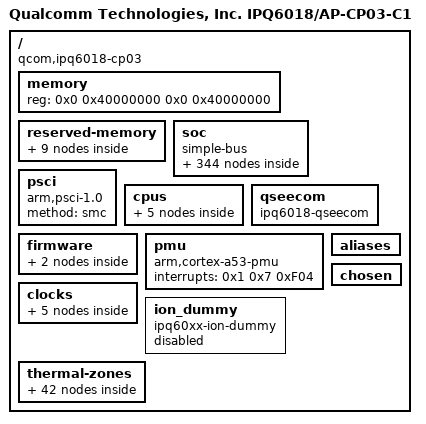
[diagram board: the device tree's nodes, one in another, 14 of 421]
/dts-v1/;
// version: 17
// last_comp_version: 16
// boot_cpuid_phys: 0x0

/ {
    model = "Qualcomm Technologies, Inc. IPQ6018/AP-CP03-C1";
    compatible = "qcom,ipq6018-cp03", "qcom,ipq6018";
    qcom,board-id = <0x8 0x0>;
    qcom,pmic-id = <0x0 0x0 0x0 0x0>;
    #address-cells = <0x2>;
    #size-cells = <0x2>;
    interrupt-parent = <0x1>;
    qcom,msm-id = <0x1A5 0x0>;
    memory {
        device_type = "memory";
        reg = <0x0 0x40000000 0x0 0x40000000>;
    };
    reserved-memory {
        #address-cells = <0x2>;
        #size-cells = <0x2>;
        ranges;
        nss@40000000 {
            no-map;
            reg = <0x0 0x40000000 0x0 0x1000000>;
        };
        uboot@4A100000 {
            no-map;
            reg = <0x0 0x4A100000 0x0 0x400000>;
        };
        sbl@4A500000 {
            no-map;
            reg = <0x0 0x4A500000 0x0 0x100000>;
        };
        tz@4A600000 {
            no-map;
            reg = <0x0 0x4A600000 0x0 0x400000>;
        };
        smem@4AA00000 {
            no-map;
            reg = <0x0 0x4AA00000 0x0 0x100000>;
            linux,phandle = <0x11>;
            phandle = <0x11>;
        };
        wcnss@4ab00000 {
            no-map;
            reg = <0x0 0x4AB00000 0x0 0x5500000>;
            linux,phandle = <0x17>;
            phandle = <0x17>;
        };
        q6_etr_dump@1 {
            no-map;
            reg = <0x0 0x50000000 0x0 0x100000>;
            linux,phandle = <0x18>;
            phandle = <0x18>;
        };
        rpm_msg_ram@0x60000 {
            no-map;
            reg = <0x0 0x60000 0x0 0x6000>;
            linux,phandle = <0x13>;
            phandle = <0x13>;
        };
        tzapp@49B00000 {
            no-map;
            reg = <0x0 0x49B00000 0x0 0x600000>;
        };
    };
    soc {
        #address-cells = <0x1>;
        #size-cells = <0x1>;
        ranges = <0x0 0x0 0x0 0xFFFFFFFF>;
        compatible = "simple-bus";
        wifi1@f00000 {
            compatible = "qcom,cnss-qcn9000";
            qcom,wlan-ramdump-dynamic = <0x400000>;
            status = "disabled";
            mhi,max-channels = <0x1E>;
            mhi,timeout = <0x2710>;
            #address-cells = <0x1>;
            #size-cells = <0x0>;
            base-addr = <0x50100000>;
            caldb-addr = <0x53000000>;
            qrtr_node_id = <0x20>;
            qca,auto-restart;
            mhi_channels {
                mhi_chan@0 {
                    reg = <0x0>;
                    label = "LOOPBACK";
                    mhi,num-elements = <0x20>;
                    mhi,event-ring = <0x1>;
                    mhi,chan-dir = <0x1>;
                    mhi,data-type = <0x0>;
                    mhi,doorbell-mode = <0x2>;
                    mhi,ee = <0x14>;
                };
                mhi_chan@1 {
                    reg = <0x1>;
                    label = "LOOPBACK";
                    mhi,num-elements = <0x20>;
                    mhi,event-ring = <0x1>;
                    mhi,chan-dir = <0x2>;
                    mhi,data-type = <0x0>;
                    mhi,doorbell-mode = <0x2>;
                    mhi,ee = <0x14>;
                };
                mhi_chan@4 {
                    reg = <0x4>;
                    label = "DIAG";
                    mhi,num-elements = <0x20>;
                    mhi,event-ring = <0x1>;
                    mhi,chan-dir = <0x1>;
                    mhi,data-type = <0x0>;
                    mhi,doorbell-mode = <0x2>;
                    mhi,ee = <0x14>;
                };
                mhi_chan@5 {
                    reg = <0x5>;
                    label = "DIAG";
                    mhi,num-elements = <0x20>;
                    mhi,event-ring = <0x1>;
                    mhi,chan-dir = <0x2>;
                    mhi,data-type = <0x0>;
                    mhi,doorbell-mode = <0x2>;
                    mhi,ee = <0x14>;
                };
                mhi_chan@20 {
                    reg = <0x14>;
                    label = "IPCR";
                    mhi,num-elements = <0x20>;
                    mhi,event-ring = <0x1>;
                    mhi,chan-dir = <0x1>;
                    mhi,data-type = <0x1>;
                    mhi,doorbell-mode = <0x2>;
                    mhi,ee = <0x14>;
                    mhi,auto-start;
                };
                mhi_chan@21 {
                    reg = <0x15>;
                    label = "IPCR";
                    mhi,num-elements = <0x20>;
                    mhi,event-ring = <0x1>;
                    mhi,chan-dir = <0x2>;
                    mhi,data-type = <0x0>;
                    mhi,doorbell-mode = <0x2>;
                    mhi,ee = <0x14>;
                    mhi,auto-queue;
                    mhi,auto-start;
                };
            };
            mhi_events {
                mhi_event@0 {
                    mhi,num-elements = <0x20>;
                    mhi,intmod = <0x1>;
                    mhi,msi = <0x1>;
                    mhi,priority = <0x1>;
                    mhi,brstmode = <0x2>;
                    mhi,data-type = <0x1>;
                };
                mhi_event@1 {
                    mhi,num-elements = <0x100>;
                    mhi,intmod = <0x1>;
                    mhi,msi = <0x2>;
                    mhi,priority = <0x1>;
                    mhi,brstmode = <0x2>;
                };
            };
            mhi_devices {
                mhi_qrtr {
                    mhi,chan = "IPCR";
                    qcom,net-id = <0x0>;
                };
            };
        };
        interrupt-controller@b000000 {
            compatible = "qcom,msm-qgic2";
            interrupt-controller;
            #interrupt-cells = <0x3>;
            reg = <0xB000000 0x1000 0xB002000 0x1000>;
            linux,phandle = <0x1>;
            phandle = <0x1>;
        };
        timer {
            compatible = "arm,armv8-timer";
            interrupts = <0x1 0x2 0xF08 0x1 0x3 0xF08 0x1 0x4 0xF08 0x1 0x1 0xF08>;
            clock-frequency = <0x16E3600>;
            always-on;
        };
        gcc@1800000 {
            compatible = "qcom,gcc-ipq6018";
            reg = <0x1800000 0x80000>;
            #clock-cells = <0x1>;
            #reset-cells = <0x1>;
            linux,phandle = <0x3>;
            phandle = <0x3>;
        };
        qcom,apss_clk@b111000 {
            compatible = "qcom,apss-ipq6018";
            reg = <0xB111000 0x6000>;
            #clock-cells = <0x1>;
            #reset-cells = <0x1>;
            linux,phandle = <0x4F>;
            phandle = <0x4F>;
        };
        arm,smmu@1E00000 {
            compatible = "arm,smmu-v2";
            reg = <0x1E00000 0x40000>;
            #iommu-cells = <0x1>;
            #global-interrupts = <0x1>;
            qcom,skip-init;
            interrupts = <0x0 0x29 0x4 0x0 0x46 0x4 0x0 0x47 0x4 0x0 0x49 0x4 0x0 0xF0 0x4 0x0 0xF1 0x4 0x0 0xF2 0x4 0x0 0xF5 0x4 0x0 0xF6 0x4 0x0 0xF7 0x4 0x0 0xF8 0x4 0x0 0xF9 0x4 0x0 0xFA 0x4 0x0 0xFB 0x4 0x0 0xFC 0x4 0x0 0xFD 0x4 0x0 0xFE 0x4 0x0 0xFF 0x4 0x0 0x35 0x4 0x0 0x36 0x4 0x0 0x3A 0x4 0x0 0x3C 0x4 0x0 0x3D 0x4 0x0 0x4C 0x4 0x0 0x4D 0x4 0x0 0x50 0x4 0x0 0x5E 0x4 0x0 0x65 0x4 0x0 0x66 0x4 0x0 0x67 0x4 0x0 0x68 0x4 0x0 0x69 0x4 0x0 0x6A 0x4>;
            status = "disabled";
            linux,phandle = <0x2>;
            phandle = <0x2>;
        };
        qcom,msm-adsprpc-mem {
            compatible = "qcom,msm-adsprpc-mem-region";
            status = "disabled";
        };
        qcom,msm_fastrpc {
            compatible = "qcom,msm-fastrpc-compute";
            qcom,rpc-latency-us = <0x263>;
            qcom,fastrpc-adsp-audio-pdr;
            qcom,fastrpc-adsp-sensors-pdr;
            qcom,fastrpc-legacy-remote-heap;
            status = "disabled";
            qcom,msm_fastrpc_compute_cb1 {
                compatible = "qcom,msm-fastrpc-compute-cb";
                label = "adsprpc-smd";
                iommus = <0x2 0x1004>;
            };
            qcom,msm_fastrpc_compute_cb2 {
                compatible = "qcom,msm-fastrpc-compute-cb";
                label = "adsprpc-smd";
                iommus = <0x2 0x1005>;
            };
            qcom,msm_fastrpc_compute_cb3 {
                compatible = "qcom,msm-fastrpc-compute-cb";
                label = "adsprpc-smd";
                iommus = <0x2 0x1006>;
            };
            qcom,msm_fastrpc_compute_cb4 {
                compatible = "qcom,msm-fastrpc-compute-cb";
                label = "adsprpc-smd";
                iommus = <0x2 0x1007>;
            };
            qcom,msm_fastrpc_compute_cb5 {
                compatible = "qcom,msm-fastrpc-compute-cb";
                label = "adsprpc-smd";
                iommus = <0x2 0x1008>;
            };
            qcom,msm_fastrpc_compute_cb6 {
                compatible = "qcom,msm-fastrpc-compute-cb";
                label = "adsprpc-smd";
                iommus = <0x2 0x1009>;
            };
            qcom,msm_fastrpc_compute_cb7 {
                compatible = "qcom,msm-fastrpc-compute-cb";
                label = "adsprpc-smd";
                iommus = <0x2 0x100A>;
            };
            qcom,msm_fastrpc_compute_cb8 {
                compatible = "qcom,msm-fastrpc-compute-cb";
                label = "adsprpc-smd";
                iommus = <0x2 0x100B>;
            };
        };
        serial@78b3000 {
            compatible = "qcom,msm-uartdm-v1.4", "qcom,msm-uartdm";
            reg = <0x78B3000 0x200>;
            interrupts = <0x0 0x134 0x4>;
            clocks = <0x3 0x54 0x3 0x43>;
            clock-names = "core", "iface";
            status = "disabled";
        };
        serial@78af000 {
            compatible = "qcom,msm-uartdm-v1.4", "qcom,msm-uartdm";
            reg = <0x78AF000 0x200>;
            interrupts = <0x0 0x6B 0x4>;
            clocks = <0x3 0x50 0x3 0x43>;
            clock-names = "core", "iface";
            status = "disabled";
        };
        serial@78b0000 {
            compatible = "qcom,msm-uartdm-v1.4", "qcom,msm-uartdm";
            reg = <0x78B0000 0x200>;
            interrupts = <0x0 0x6C 0x4>;
            clocks = <0x3 0x51 0x3 0x43>;
            clock-names = "core", "iface";
            status = "disabled";
        };
        serial@78b1000 {
            compatible = "qcom,msm-uartdm-v1.4", "qcom,msm-uartdm";
            reg = <0x78B1000 0x200>;
            interrupts = <0x0 0x132 0x4>;
            clocks = <0x3 0x52 0x3 0x43>;
            clock-names = "core", "iface";
            status = "ok";
            pinctrl-0 = <0x4>;
            pinctrl-names = "default";
        };
        qrng@e1000 {
            compatible = "qcom,prng-ipq807x";
            reg = <0xE3000 0x1000>;
            clocks = <0x3 0x88>;
            clock-names = "core";
            status = "ok";
        };
        dma@704000 {
            compatible = "qcom,bam-v1.7.0";
            reg = <0x704000 0x20000>;
            interrupts = <0x0 0xCF 0x0>;
            clocks = <0x3 0x56>;
            clock-names = "bam_clk";
            #dma-cells = <0x1>;
            qcom,ee = <0x1>;
            qcom,controlled-remotely = <0x1>;
            qcom,config-pipe-trust-reg = <0x0>;
            linux,phandle = <0x5>;
            phandle = <0x5>;
        };
        crypto@73a000 {
            compatible = "qcom,crypto-v5.1";
            reg = <0x73A000 0x6000>;
            clocks = <0x3 0x56 0x3 0x57 0x3 0x58>;
            clock-names = "iface", "bus", "core";
            dmas = <0x5 0x2 0x5 0x3>;
            dma-names = "rx", "tx";
        };
        qcom_mdss_qpic@7980000 {
            compatible = "qcom,mdss_qpic";
            reg = <0x7980000 0x24000>;
            interrupts = <0x0 0x97 0x0>;
            clocks = <0x3 0x8A 0x3 0x89>;
            clock-names = "core", "aon";
            dmas = <0x6 0x6>;
            dma-names = "chan";
            status = "disabled";
        };
        qcom_mdss_qpic_panel {
            compatible = "qcom,mdss-qpic-panel";
            label = "qpic lcd panel";
            qcom,mdss-pan-res = <0x320 0x1E0>;
            qcom,mdss-pan-bpp = <0x12>;
            qcom,refresh_rate = <0x3C>;
            status = "disabled";
        };
        ssphy@78000 {
            compatible = "qcom,usb-ssphy-qmp";
            reg = <0x78000 0x45C 0x193F244 0x4 0x8AF8800 0x100 0x7E000 0x18>;
            reg-names = "qmp_phy_base", "vls_clamp_reg", "qscratch_base", "ahb2phy_base";
            qcom,qmp-phy-init-seq = <0xAC 0x14 0x1A 0x0 0x34 0x8 0x8 0x0 0x174 0x30 0x30 0x0 0x3C 0x6 0x6 0x0 0xB4 0x0 0x0 0x0 0xB8 0x8 0x8 0x0 0x194 0x6 0x6 0x3E8 0x19C 0x1 0x1 0x0 0x178 0x0 0x0 0x0 0xD0 0x68 0x68 0x0 0xDC 0xAB 0xAB 0x0 0xE0 0xAA 0xAA 0x0 0xE4 0x2 0x2 0x0 0x78 0x9 0x9 0x0 0x84 0x16 0x16 0x0 0x90 0x28 0x28 0x0 0x108 0xA0 0xA0 0x0 0x10C 0x0 0x0 0x0 0x184 0xA 0xA 0x0 0x4C 0xAA 0xAA 0x0 0x50 0x29 0x29 0x0 0x54 0x0 0x0 0x0 0xC8 0x0 0x0 0x0 0x18C 0x0 0x0 0x0 0xCC 0x0 0x0 0x0 0x128 0x0 0x0 0x0 0xC 0xA 0xA 0x0 0x10 0x1 0x1 0x0 0x1C 0x7D 0x7D 0x0 0x20 0x1 0x1 0x0 0x14 0x0 0x0 0x0 0x18 0x0 0x0 0x0 0x24 0xA 0xA 0x0 0x28 0x5 0x5 0x0 0x48 0xF 0xF 0x0 0x70 0xF 0xF 0x0 0x100 0x80 0x80 0x0 0x440 0xB 0xB 0x0 0x4D8 0x2 0x2 0x0 0x4DC 0x6C 0x6C 0x0 0x4E0 0xBB 0xB8 0x0 0x508 0x77 0x77 0x0 0x50C 0x80 0x80 0x0 0x514 0x3 0x3 0x0 0x51C 0x16 0x16 0x0 0x448 0x75 0x75 0x0 0x454 0x0 0x0 0x0 0x40C 0xA 0xA 0x0 0x41C 0x6 0x6 0x0 0x510 0x0 0x0 0x0 0x268 0x45 0x45 0x0 0x2AC 0x12 0x12 0x0 0x294 0x6 0x6 0x0 0x254 0x0 0x0 0x0 0x8C8 0x83 0x83 0x0 0x8C4 0x2 0x2 0x0 0x8CC 0x9 0x9 0x0 0x8D0 0xA2 0xA2 0x0 0x8D4 0x85 0x85 0x0 0x880 0xD1 0xD1 0x0 0x884 0x1F 0x1F 0x0 0x888 0x47 0x47 0x0 0x80C 0x9F 0x9F 0x0 0x824 0x17 0x17 0x0 0x828 0xF 0xF 0x0 0x8B8 0x75 0x75 0x0 0x8BC 0x13 0x13 0x0 0x8B0 0x86 0x86 0x0 0x8A0 0x4 0x4 0x0 0x88C 0x44 0x44 0x0 0x870 0xE7 0xE7 0x0 0x874 0x3 0x3 0x0 0x878 0x40 0x40 0x0 0x87C 0x0 0x0 0x0 0x9D8 0x88 0x88 0x0 0xFFFFFFFF 0xFFFFFFFF 0x0 0x0>;
            qcom,qmp-phy-reg-offset = <0x988 0x98C 0x990 0x994 0x974 0x8D8 0x8DC 0x804 0x800 0x808>;
            clocks = <0x3 0x9D 0x3 0xA1>;
            clock-names = "aux_clk", "pipe_clk";
            resets = <0x3 0x27 0x3 0x28>;
            reset-names = "usb3_phy_reset", "usb3phy_phy_reset";
            status = "ok";
            linux,phandle = <0x9>;
            phandle = <0x9>;
        };
        qusb@79000 {
            compatible = "qcom,qusb2phy";
            reg = <0x79000 0x180 0x8AF8800 0x400 0x1841030 0x4 0x8A0C12C 0x4>;
            reg-names = "qusb_phy_base", "qscratch_base", "ref_clk_addr", "usb3_guctl_addr";
            qcom,qusb-phy-init-seq = <0x14 0x0 0xF8 0x80 0xB3 0x84 0x83 0x88 0xC0 0x8C 0x30 0x8 0x79 0xC 0x21 0x10 0x0 0x90 0x0 0x18 0x14 0x9C 0x80 0x4 0x9F 0x1C>;
            phy_type = "utmi";
            resets = <0x3 0x2B>;
            reset-names = "usb2_phy_reset";
            status = "ok";
            linux,phandle = <0x8>;
            phandle = <0x8>;
        };
        qusb@59000 {
            compatible = "qcom,qusb2phy";
            reg = <0x59000 0x180 0x70F8800 0x400 0x1841030 0x4 0x700C12C 0x4>;
            reg-names = "qusb_phy_base", "qscratch_base", "ref_clk_addr", "usb3_guctl_addr";
            qcom,qusb-phy-init-seq = <0x14 0x0 0xF8 0x80 0xB3 0x84 0x83 0x88 0xC0 0x8C 0x30 0x8 0x79 0xC 0x21 0x10 0x0 0x90 0x0 0x18 0x14 0x9C 0x80 0x4 0x9F 0x1C>;
            phy_type = "utmi";
            resets = <0x3 0x2C>;
            reset-names = "usb2_phy_reset";
            status = "disabled";
            linux,phandle = <0xA>;
            phandle = <0xA>;
        };
        dbm@0x8AF8000 {
            compatible = "qcom,usb-dbm-1p5";
            reg = <0x8AF8000 0x300>;
            qcom,reset-ep-after-lpm-resume;
            linux,phandle = <0x7>;
            phandle = <0x7>;
        };
        usb3@8A00000 {
            compatible = "qcom,ipq6018-dwc3";
            #address-cells = <0x1>;
            #size-cells = <0x1>;
            ranges;
            reg = <0x8AF8800 0x100 0x8A00000 0xCD00>;
            reg-names = "qscratch_base", "dwc3_base";
            clocks = <0x3 0xB9 0x3 0xBA 0x3 0x9E 0x3 0xA2 0x3 0x9F 0x3 0xA0 0x3 0x9D 0x3 0xA1>;
            clock-names = "snoc_bus_timeout2", "sys_noc_axi", "master", "sleep", "mock_utmi", "cfg_ahb_clk", "aux_clk", "pipe_clk";
            assigned-clocks = <0x3 0xBA 0x3 0x9E 0x3 0x9F>;
            assigned-clock-rates = <0x7F27450 0x7F27450 0x16E3600>;
            qca,host = <0x1>;
            qcom,usb-dbm = <0x7>;
            status = "ok";
            dwc3@8A00000 {
                compatible = "snps,dwc3";
                reg = <0x8A00000 0xCD00>;
                interrupts = <0x0 0x8C 0x0>;
                usb-phy = <0x8 0x9>;
                snps,dis_ep_cache_eviction;
                tx-fifo-resize;
                snps,usb3-u1u2-disable;
                snps,nominal-elastic-buffer;
                snps,is-utmi-l1-suspend;
                snps,hird-threshold = [00];
                snps,dis_u2_susphy_quirk;
                snps,dis_u3_susphy_quirk;
                snps,quirk-ref-clock-adjustment = <0xA87F0>;
                snps,quirk-ref-clock-period = <0x29>;
                dr_mode = "host";
            };
        };
        qcom,usbbam@8B04000 {
            compatible = "qcom,usb-bam-msm";
            reg = <0x8B04000 0x17000>;
            interrupt-parent = <0x1>;
            interrupts = <0x0 0x87 0x0>;
            qcom,bam-type = <0x0>;
            qcom,usb-bam-fifo-baseaddr = <0x4A100000>;
            qcom,usb-bam-num-pipes = <0x4>;
            qcom,ignore-core-reset-ack;
            qcom,disable-clk-gating;
            qcom,usb-bam-override-threshold = <0x4001>;
            qcom,usb-bam-max-mbps-highspeed = <0x190>;
            qcom,usb-bam-max-mbps-superspeed = <0xE10>;
            qcom,reset-bam-on-connect;
            qcom,pipe0 {
                label = "ssusb-qdss-in-0";
                qcom,usb-bam-mem-type = <0x2>;
                qcom,dir = <0x1>;
                qcom,pipe-num = <0x0>;
                qcom,peer-bam = <0x0>;
                qcom,peer-bam-physical-address = <0x6064000>;
                qcom,src-bam-pipe-index = <0x0>;
                qcom,dst-bam-pipe-index = <0x0>;
                qcom,data-fifo-offset = <0x0>;
                qcom,data-fifo-size = <0xE00>;
                qcom,descriptor-fifo-offset = <0xE00>;
                qcom,descriptor-fifo-size = <0x200>;
            };
        };
        extcon_usb {
            compatible = "linux,extcon-usb-gpio";
            status = "disabled";
        };
        usb2@7000000 {
            compatible = "qcom,ipq6018-dwc3";
            #address-cells = <0x1>;
            #size-cells = <0x1>;
            ranges;
            reg = <0x70F8800 0x100 0x7000000 0xCD00>;
            reg-names = "qscratch_base", "dwc3_base";
            clocks = <0x3 0xA3 0x3 0xA6 0x3 0xA4 0x3 0xA5>;
            clock-names = "master", "sleep", "mock_utmi", "cfg_ahb_clk";
            assigned-clocks = <0x3 0xA3 0x3 0xA4>;
            assigned-clock-rates = <0x7F27450 0x16E3600>;
            qca,host = <0x1>;
            status = "disabled";
            dwc3@7000000 {
                compatible = "snps,dwc3";
                reg = <0x7000000 0xCD00>;
                interrupts = <0x0 0x63 0x0>;
                usb-phy = <0xA>;
                snps,dis_ep_cache_eviction;
                tx-fifo-resize;
                snps,usb3-u1u2-disable;
                snps,nominal-elastic-buffer;
                snps,is-utmi-l1-suspend;
                snps,hird-threshold = [00];
                snps,dis_u2_susphy_quirk;
                snps,dis_u3_susphy_quirk;
                snps,quirk-ref-clock-adjustment = <0xA87F0>;
                snps,quirk-ref-clock-period = <0x29>;
                dr_mode = "host";
            };
        };
        phy@84000 {
            compatible = "qca,pcie-qmp-phy-gen3";
            reg = <0x84000 0x1000>;
            phy-type = "gen3";
            qcom,qmp-pcie-phy-init-seq = <0x840 0x3 0x1C 0x7D 0x20 0x1 0x24 0xA 0x28 0x5 0x2C 0x8 0x30 0x4 0x3C 0x18 0x40 0x90 0x44 0x2 0x48 0x7 0x50 0xF 0x54 0xD4 0x58 0x14 0x60 0xAA 0x64 0x29 0x74 0xF 0xFFFFFFFF 0x1 0x80 0x9 0x84 0x9 0x88 0x16 0x8C 0x16 0x90 0x28 0x94 0x28 0xA4 0x1 0xA8 0x8 0xB0 0x20 0xC4 0x42 0xCC 0x68 0xD0 0x53 0xD8 0xAB 0xDC 0xAA 0xE0 0x2 0xE4 0x55 0xE8 0x55 0xEC 0x5 0x100 0xA0 0x108 0xA0 0x124 0x24 0x128 0x2 0x12C 0xB4 0x130 0x3 0x16C 0x32 0x170 0x1 0x184 0x0 0x18C 0x6 0x194 0x5 0x1B4 0x8 0x23C 0x2 0x284 0x6 0x29C 0x12 0x408 0xC 0x414 0x2 0x434 0x7F 0x444 0x70 0x4EC 0x61 0x4F0 0x4 0x4F4 0x1E 0x4F8 0xC0 0x4FC 0x0 0x510 0x73 0x514 0x80 0x518 0x1C 0x51C 0x3 0x524 0x14 0x570 0xF0 0x574 0x1 0x578 0x2F 0x57C 0xD3 0x580 0x40 0x584 0x1 0x588 0x2 0x58C 0xC8 0x590 0x9 0x594 0xB1 0x598 0x0 0x59C 0x2 0x5A0 0xC8 0x5A4 0x9 0x5A8 0xB1 0x5B4 0x4 0x898 0x1 0x8DC 0xD 0x96C 0x10 0x988 0xAA 0x9A4 0x1 0x9D8 0x1 0x9EC 0x1 0xC0C 0xD 0xC14 0x7 0xC1C 0xC1 0xC40 0x1 0xC48 0x1 0xC90 0x0 0xCA0 0x11 0xCBC 0x0 0xCE0 0x58 0x800 0x0 0x844 0x3>;
            #phy-cells = <0x0>;
            clocks = <0x3 0x87>;
            clock-names = "pipe_clk";
            resets = <0x3 0x45 0x3 0x46>;
            reset-names = "phy", "phy_phy";
            status = "disabled";
            linux,phandle = <0xB>;
            phandle = <0xB>;
        };
        pci@20000000 {
            compatible = "qcom,pcie-ipq6018";
            reg = <0x20000000 0xF1D 0x20000F20 0xA8 0x20001000 0x1000 0x80000 0x2000 0x20100000 0x1000>;
            reg-names = "dbi", "elbi", "dm_iatu", "parf", "config";
            device_type = "pci";
            linux,pci-domain = <0x0>;
            bus-range = <0x0 0xFF>;
            num-lanes = <0x1>;
            #address-cells = <0x3>;
            #size-cells = <0x2>;
            phys = <0xB>;
            phy-names = "pciephy";
            ranges = <0x81000000 0x0 0x20200000 0x20200000 0x0 0x100000 0x82000000 0x0 0x20300000 0x20300000 0x0 0x10000000>;
            interrupts = <0x0 0x34 0x0 0x0 0x1A0 0x0 0x0 0x1A1 0x0 0x0 0x1A2 0x0 0x0 0x1A3 0x0 0x0 0x1A4 0x0 0x0 0x1A5 0x0 0x0 0x1A6 0x0 0x0 0x1A7 0x0 0x0 0x1A8 0x0 0x0 0x1A9 0x0 0x0 0x1AA 0x0 0x0 0x1AB 0x0 0x0 0x1AC 0x0 0x0 0x1AD 0x0 0x0 0x1AE 0x0 0x0 0x1AF 0x0>;
            interrupt-names = "msi", "msi_0", "msi_1", "msi_2", "msi_3", "msi_4", "msi_5", "msi_6", "msi_7", "msi_8", "msi_9", "msi_10", "msi_11", "msi_12", "msi_13", "msi_14", "msi_15";
            #interrupt-cells = <0x1>;
            interrupt-map-mask = <0x0 0x0 0x0 0x7>;
            interrupt-map = <0x0 0x0 0x0 0x1 0x1 0x0 0x4B 0x4 0x0 0x0 0x0 0x2 0x1 0x0 0x4E 0x4 0x0 0x0 0x0 0x3 0x1 0x0 0x4F 0x4 0x0 0x0 0x0 0x4 0x1 0x0 0x53 0x4>;
            clocks = <0x3 0xBB 0x3 0x85 0x3 0x86 0x3 0x83 0x3 0x84 0x3 0xC6 0x3 0xC7>;
            clock-names = "sys_noc", "axi_m", "axi_s", "ahb", "aux", "axi_bridge", "rchng";
            resets = <0x3 0x60 0x3 0x61 0x3 0x62 0x3 0x63 0x3 0x64 0x3 0x65 0x3 0x66 0x3 0x67>;
            reset-names = "pipe", "sleep", "sticky", "axi_m", "axi_s", "ahb", "axi_m_sticky", "axi_s_sticky";
            perst-gpio = <0xC 0x3C 0x1>;
            qcom,msi-gicm-addr = <0xB00A040>;
            qcom,msi-gicm-base = <0x1C0>;
            status = "disabled";
            pcie0_rp {
                reg = <0x0 0x0 0x0 0x0 0x0>;
            };
        };
        qcom,diag@0 {
            compatible = "qcom,diag";
            status = "ok";
        };
        qcom,gadget_diag@0 {
            compatible = "qcom,gadget-diag";
            status = "disabled";
        };
        dma@7884000 {
            compatible = "qcom,bam-v1.7.0";
            reg = <0x7884000 0x2B000>;
            interrupts = <0x0 0xEE 0x0>;
            clocks = <0x3 0x43>;
            clock-names = "bam_clk";
            #dma-cells = <0x1>;
            qcom,ee = <0x0>;
            linux,phandle = <0xD>;
            phandle = <0xD>;
        };
        i2c@78b6000 {
            compatible = "qcom,i2c-qup-v2.2.1";
            #address-cells = <0x1>;
            #size-cells = <0x0>;
            reg = <0x78B6000 0x600>;
            interrupts = <0x0 0x60 0x4>;
            clocks = <0x3 0x43 0x3 0x46>;
            clock-names = "iface", "core";
            clock-frequency = <0x61A80>;
            dmas = <0xD 0xF 0xD 0xE>;
            dma-names = "rx", "tx";
            status = "disabled";
        };
        i2c@78b7000 {
            compatible = "qcom,i2c-qup-v2.2.1";
            #address-cells = <0x1>;
            #size-cells = <0x0>;
            reg = <0x78B7000 0x600>;
            interrupts = <0x0 0x61 0x4>;
            clocks = <0x3 0x43 0x3 0x48>;
            clock-names = "iface", "core";
            clock-frequency = <0x61A80>;
            dmas = <0xD 0x11 0xD 0x10>;
            dma-names = "rx", "tx";
            status = "disabled";
        };
        spi@78b5000 {
            compatible = "qcom,spi-qup-v2.2.1";
            #address-cells = <0x1>;
            #size-cells = <0x0>;
            reg = <0x78B5000 0x600>;
            interrupts = <0x0 0x5F 0x0>;
            spi-max-frequency = <0x2FAF080>;
            clocks = <0x3 0x45 0x3 0x43>;
            clock-names = "core", "iface";
            dmas = <0xD 0xC 0xD 0xD>;
            dma-names = "tx", "rx";
            status = "ok";
            pinctrl-0 = <0xE>;
            pinctrl-names = "default";
            cs-select = <0x0>;
            m25p80@0 {
                #address-cells = <0x1>;
                #size-cells = <0x1>;
                reg = <0x0>;
                compatible = "n25q128a11";
                linux,modalias = "m25p80", "n25q128a11";
                spi-max-frequency = <0x2FAF080>;
                use-default-sizes;
            };
        };
        spi@78b6000 {
            compatible = "qcom,spi-qup-v2.2.1";
            #address-cells = <0x1>;
            #size-cells = <0x0>;
            reg = <0x78B6000 0x600>;
            interrupts = <0x0 0x60 0x0>;
            spi-max-frequency = <0x2FAF080>;
            clocks = <0x3 0x47 0x3 0x43>;
            clock-names = "core", "iface";
            dmas = <0xD 0xE 0xD 0xF>;
            dma-names = "tx", "rx";
            status = "disabled";
        };
        pwm {
            compatible = "qca,ipq6018-pwm";
            reg = <0x1941010 0x20>;
            clocks = <0x3 0xC1>;
            clock-names = "core";
            src-freq = <0x5F5E100>;
            pwm-base-index = <0x0>;
            used-pwm-indices = <0x1 0x1 0x1 0x1>;
            status = "disabled";
        };
        dcc@b3000 {
            compatible = "qca,dcc";
            status = "ok";
            reg = <0xB3000 0x1000 0xB4000 0x800 0x4A2000 0x8>;
            reg-names = "dcc-base", "dcc-ram-base", "gcnt_lo_hi";
            clocks = <0x3 0xC4>;
            clock-names = "dcc_clk";
            no_xpu_support;
            qca,save-reg;
        };
        syscon@1905000 {
            compatible = "syscon";
            reg = <0x1905000 0x8000>;
            linux,phandle = <0xF>;
            phandle = <0xF>;
        };
        hwlock@1905000 {
            compatible = "qcom,tcsr-mutex";
            syscon = <0xF 0x0 0x80>;
            #hwlock-cells = <0x1>;
            linux,phandle = <0x12>;
            phandle = <0x12>;
        };
        syscon@1945000 {
            compatible = "syscon";
            reg = <0x1945000 0xE000>;
            linux,phandle = <0x22>;
            phandle = <0x22>;
        };
        mailbox@b111000 {
            compatible = "qcom,msm8996-apcs-hmss-global";
            qcom,ipc = <0x10 0x8 0x8>;
            #mbox-cells = <0x1>;
            linux,phandle = <0x23>;
            phandle = <0x23>;
        };
        mailboxlpass@b111000 {
            compatible = "qcom,msm8996-apcs-hmss-global";
            qcom,ipc = <0x10 0x8 0x17>;
            #mbox-cells = <0x1>;
            linux,phandle = <0x24>;
            phandle = <0x24>;
        };
        mailboxrpm@b111000 {
            compatible = "qcom,msm8996-apcs-hmss-global";
            qcom,ipc = <0x10 0x8 0x0>;
            #mbox-cells = <0x1>;
            linux,phandle = <0x14>;
            phandle = <0x14>;
        };
        qcom,smem@4AA00000 {
            compatible = "qcom,smem";
            memory-region = <0x11>;
            hwlocks = <0x12 0x0>;
        };
        qcom,glink-smem-native-xprt-modem@4AA00000 {
            compatible = "qcom,glink-smem-native-xprt";
            reg = <0x4AA00000 0x100000 0xB111008 0x4>;
            reg-names = "smem", "irq-reg-base";
            qcom,irq-mask = <0x100>;
            interrupts = <0x0 0x141 0x1>;
            label = "mpss";
            qcom,subsys-id = <0x1>;
            smem-entry = <0x1DE 0x1DF 0x1E0>;
            smem-entry-names = "ch", "tx_fifo", "rx_fifo";
        };
        qcom,glink-smem-native-xprt-adsp@4AA00000 {
            compatible = "qcom,glink-smem-native-xprt";
            reg = <0x4AA00000 0x100000 0xB111008 0x4>;
            reg-names = "smem", "irq-reg-base";
            qcom,irq-mask = <0x800000>;
            interrupts = <0x0 0x18 0x1>;
            label = "adsp";
            qcom,subsys-id = <0x2>;
            smem-entry = <0x1DE 0x1DF 0x1E0>;
            smem-entry-names = "ch", "tx_fifo", "rx_fifo";
            status = "disabled";
        };
        qcom,glink-rpm-native-xprt@60000 {
            compatible = "qcom,glink-rpm-native-xprt";
            reg = <0x60000 0x6000 0xB111008 0x4>;
            reg-names = "msgram", "irq-reg-base";
            qcom,irq-mask = <0x1>;
            interrupts = <0x0 0xA8 0x1>;
            label = "rpm";
            qcom,subsys-id = <0x6>;
            status = "ok";
        };
        qcom,rpmsg-rpm@60000 {
            compatible = "qcom,glink-rpm";
            qcom,rpm-msg-ram = <0x13>;
            interrupts = <0x0 0xA8 0x1>;
            label = "rpm";
            qcom,subsys-id = <0x6>;
            mboxes = <0x14 0x8>;
            status = "ok";
            glink_edge {
                qcom,glink-channels = "rpm_requests";
                qcom,rpm-channel-type = <0xF>;
            };
        };
        qcom,rpm-glink {
            compatible = "qcom,rpm-glink";
            qcom,glink-edge = "rpm";
            rpm-channel-name = "rpm_requests";
            qcom,rpm-channel-type = <0xF>;
            status = "ok";
        };
        qcom,ipc_router {
            compatible = "qcom,ipc_router";
            qcom,node-id = <0x1>;
        };
        qcom,ipc_router_modem_xprt {
            compatible = "qcom,ipc_router_glink_xprt";
            qcom,ch-name = "IPCRTR";
            qcom,xprt-remote = "mpss";
            qcom,glink-xprt = "smem";
            qcom,xprt-linkid = <0x1>;
            qcom,xprt-version = <0x1>;
            qcom,fragmented-data;
        };
        qcom,ipc_router_adsp_xprt {
            compatible = "qcom,ipc_router_glink_xprt";
            qcom,ch-name = "IPCRTR";
            qcom,xprt-remote = "adsp";
            qcom,glink-xprt = "smem";
            qcom,xprt-linkid = <0x1>;
            qcom,xprt-version = <0x1>;
            qcom,fragmented-data;
            status = "disabled";
        };
        syscon@b111000 {
            compatible = "syscon";
            reg = <0xB111000 0x1000>;
            linux,phandle = <0x10>;
            phandle = <0x10>;
        };
        smp2p-wcss {
            compatible = "qcom,smp2p";
            qcom,smem = <0x1B3 0x1AC>;
            interrupt-parent = <0x1>;
            interrupts = <0x0 0x142 0x1>;
            qcom,ipc = <0x10 0x8 0x9>;
            qcom,local-pid = <0x0>;
            qcom,remote-pid = <0x1>;
            master-kernel {
                qcom,entry-name = "master-kernel";
                qcom,smp2p-feature-ssr-ack;
                #qcom,smem-state-cells = <0x1>;
                linux,phandle = <0x16>;
                phandle = <0x16>;
            };
            slave-kernel {
                qcom,entry-name = "slave-kernel";
                interrupt-controller;
                #interrupt-cells = <0x2>;
                linux,phandle = <0x15>;
                phandle = <0x15>;
            };
        };
        smp2p-adsp {
            compatible = "qcom,smp2p";
            qcom,smem = <0x1BB 0x1AD>;
            status = "disabled";
            interrupt-parent = <0x1>;
            interrupts = <0x0 0x1A 0x1>;
            qcom,ipc = <0x10 0x8 0x15>;
            qcom,local-pid = <0x0>;
            qcom,remote-pid = <0x2>;
            master-kernel {
                qcom,entry-name = "master-kernel";
                qcom,smp2p-feature-ssr-ack;
                #qcom,smem-state-cells = <0x1>;
                linux,phandle = <0x1C>;
                phandle = <0x1C>;
            };
            slave-kernel {
                qcom,entry-name = "slave-kernel";
                interrupt-controller;
                #interrupt-cells = <0x2>;
                linux,phandle = <0x1B>;
                phandle = <0x1B>;
            };
        };
        q6v5_wcss@CD00000 {
            compatible = "qca,q6v5-wcss-rproc-ipq60xx";
            firmware = "IPQ6018/q6_fw.mdt";
            reg = <0xCD00000 0x4040 0x194F000 0x10 0x1952000 0x10 0x4AB000 0x20 0x1818000 0x110 0x1859000 0x10 0x1945000 0x10>;
            reg-names = "wcss-base", "tcsr-q6-base", "tcsr-base", "mpm-base", "gcc-wcss-bcr-base", "gcc-wcss-misc-base", "tcsr-global";
            clocks = <0x3 0xCE 0x3 0xCF 0x3 0xD0 0x3 0xD1 0x3 0xCB 0x3 0xCC 0x3 0xCD 0x3 0xD2 0x3 0xD4>;
            clock-names = "wcss_axi_m_clk", "sys_noc_wcss_ahb_clk", "q6_axim_clk", "q6ss_atbm_clk", "q6ss_pclkdbg_clk", "q6_tsctr_1to2_clk", "wcss_core_tbu_clk", "wcss_q6_tbu_clk", "gcc_q6_ahb_clk";
            qca,auto-restart;
            qca,extended-intc;
            qca,sec-reset-cmd = <0x18>;
            qca,secure;
            interrupts-extended = <0x1 0x0 0x145 0x1 0x15 0x0 0x0 0x15 0x1 0x0 0x15 0x3 0x0>;
            interrupt-names = "wdog", "qcom,gpio-err-fatal", "qcom,gpio-err-ready", "qcom,gpio-stop-ack";
            qcom,smem-states = <0x16 0x0 0x16 0x1>;
            qcom,smem-state-names = "shutdown", "stop";
            memory-region = <0x17 0x18>;
            linux,phandle = <0x1A>;
            phandle = <0x1A>;
        };
        q6v5_m3 {
            compatible = "qca,q6v5-m3-rproc";
            firmware = "IPQ6018/m3_fw.mdt";
            qca,auto-restart;
            qcom,restart-group = <0x19 0x1A>;
            linux,phandle = <0x19>;
            phandle = <0x19>;
        };
        q6v6_adsp@AB00000 {
            status = "disabled";
            compatible = "qca,q6v6-adsp-rproc";
            firmware = "IPQ6018/adsp.mdt";
            reg = <0xAB00000 0x4040 0x181F000 0x4 0xA000000 0x48000 0x1954010 0x20>;
            reg-names = "adsp-base", "gcc-adsp-bcr-base", "adsp-cc-base", "tcsr-base";
            qca,extended-intc;
            qca,sec-reset-cmd = <0x18>;
            qca,secure;
            interrupts-extended = <0x1 0x0 0x1E 0x1 0x1B 0x0 0x0 0x1B 0x1 0x0 0x1B 0x3 0x0>;
            interrupt-names = "wdog", "qcom,gpio-err-fatal", "qcom,gpio-err-ready", "qcom,gpio-stop-ack";
            qcom,smem-states = <0x1C 0x0 0x1C 0x1>;
            qcom,smem-state-names = "shutdown", "stop";
            clocks = <0x3 0xF5 0x3 0xF6 0x3 0xE4 0x3 0xE5 0x3 0xE6 0x3 0xE7 0x3 0xE8 0x3 0xE9 0x3 0xEA 0x3 0xEB 0x3 0xEF>;
            clock-names = "mem_noc_lpass_clk", "snoc_lpass_cfg_clk", "lpass_core_axim_clk", "lpass_snoc_cfg_clk", "lpass_q6_axim_clk", "lpass_q6_atbm_at_clk", "lpass_q6_pclkdbg_clk", "lpass_q6ss_tsctr_1to2_clk", "lpass_q6ss_trig_clk", "lpass_tbu_clk", "pcnoc_lpass_clk";
        };
        qcom,adsprpc_loader {
            compatible = "qti,adsprpc-loader";
            status = "disabled";
        };
        qcom,glink-ssr-modem {
            compatible = "qcom,glink_ssr";
            label = "q6v5-wcss";
            qcom,edge = "mpss";
            qca,no-notify-edges;
            qcom,xprt = "smem";
        };
        qcom,glink-ssr-adsp {
            compatible = "qcom,glink_ssr";
            label = "q6v6-adsp";
            qcom,edge = "adsp";
            qcom,notify-edges = <0x1D>;
            qcom,xprt = "smem";
            status = "disabled";
        };
        qcom,glink-ssr-rpm {
            compatible = "qcom,glink_ssr";
            label = "rpm";
            qcom,edge = "rpm";
            qcom,no-notify-edges;
            qcom,xprt = "smem";
            linux,phandle = <0x1D>;
            phandle = <0x1D>;
        };
        dma@7984000 {
            compatible = "qcom,bam-v1.7.0";
            reg = <0x7984000 0x1A000>;
            interrupts = <0x0 0x92 0x0>;
            clocks = <0x3 0x89>;
            clock-names = "bam_clk";
            #dma-cells = <0x1>;
            qcom,ee = <0x0>;
            status = "ok";
            linux,phandle = <0x6>;
            phandle = <0x6>;
        };
        qcom,sps {
            compatible = "qcom,msm_sps_4k";
            qcom,pipe-attr-ee;
        };
        qpic-nand@79b0000 {
            compatible = "qcom,ebi2-nandc-bam-v1.5.0";
            reg = <0x79B0000 0x10000>;
            #address-cells = <0x1>;
            #size-cells = <0x0>;
            clocks = <0x3 0x8A 0x3 0x89>;
            clock-names = "core", "aon";
            param-read-addr-cycle = <0x1>;
            dmas = <0x6 0x0 0x6 0x1 0x6 0x2>;
            dma-names = "tx", "rx", "cmd";
            status = "ok";
            pinctrl-0 = <0x1E>;
            pinctrl-names = "default";
            nandcs@0 {
                compatible = "qcom,nandcs";
                reg = <0x0>;
                #address-cells = <0x1>;
                #size-cells = <0x1>;
                nand-ecc-strength = <0x4>;
                nand-ecc-step-size = <0x200>;
                nand-bus-width = <0x8>;
            };
        };
        sdcc1ice@7808000 {
            compatible = "qcom,ice";
            reg = <0x7808000 0x2000>;
            interrupts = <0x0 0x138 0x0>;
            qcom,msm-bus,vectors-KBps = <0x4E 0x200 0x0 0x0 0x4E 0x200 0x3E8 0x0>;
            qcom,bus-vector-names = "MIN", "MAX";
            qcom,instance-type = "sdcc";
            linux,phandle = <0x1F>;
            phandle = <0x1F>;
        };
        sdhci@7804000 {
            compatible = "qcom,sdhci-msm-v5";
            reg = <0x7804000 0x1000 0x7805000 0x1000>;
            reg-names = "hc_mem", "cmdq_mem";
            interrupts = <0x0 0x7B 0x0 0x0 0x8A 0x0>;
            interrupt-names = "hc_irq", "pwr_irq";
            qcom,bus-width = <0x8>;
            sdhc-msm-crypto = <0x1F>;
            qcom,max_clk = <0xB71B000>;
            qcom,dedicated-io = <0x1>;
            qcom,vdd-voltage-level = <0x2C4020 0x2C4020>;
            qcom,vdd-current-level = <0xC8 0x8B290>;
            qcom,vdd-io-lpm-sup;
            qcom,vdd-io-voltage-level = <0x1B7740 0x1B7740>;
            qcom,vdd-io-current-level = <0xC8 0x4F588>;
            qcom,vdd-io-always-on;
            qcom,cpu-dma-latency-us = <0x2BD>;
            qcom,msm-bus,name = "sdhc1";
            qcom,msm-bus,num-cases = <0x9>;
            qcom,msm-bus,num-paths = <0x1>;
            qcom,msm-bus,vectors-KBps = <0x4E 0x200 0x0 0x0 0x4E 0x200 0x416 0xC80 0x4E 0x200 0xCC3E 0x27100 0x4E 0x200 0xFF50 0x30D40 0x4E 0x200 0x1FE9E 0x61A80 0x4E 0x200 0x3FD3E 0xC3500 0x4E 0x200 0x3FD3E 0xC3500 0x4E 0x200 0x3FD3E 0xC3500 0x4E 0x200 0x146CC2 0x3E8000>;
            qcom,bus-bw-vectors-bps = <0x0 0x61A80 0x1312D00 0x17D7840 0x2FAF080 0x5F5E100 0xBEBC200 0x17D78400 0xFFFFFFFF>;
            clocks = <0x3 0x8B 0x3 0x8C 0x3 0xC3>;
            clock-names = "iface_clk", "core_clk", "ice_core_clk";
            qcom,ice-clk-rates = <0x9896800 0x12646790>;
            qcom,large-address-bus;
            qcom,disable-aggressive-pm;
            qcom,clk-rates = <0x61A80 0x17D7840 0x2FAF080 0x5F5E100 0xB71B000>;
            qcom,bus-speed-mode = "HS200_1p8v", "DDR_1p8v";
            qcom,nonremovable;
            status = "disabled";
        };
        sdhci_sd@7804000 {
            compatible = "qcom,sdhci-msm-v5";
            reg = <0x7804000 0x1000>;
            reg-names = "hc_mem";
            interrupts = <0x0 0x7B 0x0 0x0 0x8A 0x0>;
            interrupt-names = "hc_irq", "pwr_irq";
            qcom,max_clk = <0xB71B000>;
            qcom,bus-width = <0x4>;
            qcom,dedicated-io = <0x1>;
            qcom,vdd-voltage-level = <0x2D0370 0x2D0370>;
            qcom,vdd-current-level = <0x3A98 0x61A80>;
            qcom,vdd-io-lpm-sup;
            qcom,vdd-io-voltage-level = <0x1B7740 0x2D0370>;
            qcom,vdd-io-current-level = <0xC8 0x55F0>;
            qcom,vdd-io-always-on;
            qcom,cpu-dma-latency-us = <0x2BD>;
            qcom,msm-bus,name = "sdhc2";
            qcom,msm-bus,num-cases = <0x8>;
            qcom,msm-bus,num-paths = <0x1>;
            qcom,msm-bus,vectors-KBps = <0x51 0x200 0x0 0x0 0x51 0x200 0x416 0xC80 0x51 0x200 0xCC3E 0x27100 0x51 0x200 0xFF50 0x30D40 0x51 0x200 0x1FE9E 0x61A80 0x51 0x200 0x3FD3E 0xC3500 0x51 0x200 0x3FD3E 0xC3500 0x51 0x200 0x146CC2 0x3E8000>;
            qcom,bus-bw-vectors-bps = <0x0 0x61A80 0x1312D00 0x17D7840 0x2FAF080 0x5F5E100 0xBEBC200 0xFFFFFFFF>;
            clocks = <0x3 0x8B 0x3 0x8C>;
            clock-names = "iface_clk", "core_clk";
            qcom,large-address-bus;
            qcom,disable-aggressive-pm;
            qcom,clk-rates = <0x61A80 0x17D7840 0x2FAF080 0x5F5E100 0xB71B000>;
            qcom,bus-speed-mode = "HS200_1p8v", "DDR_1p8v";
            status = "disabled";
        };
        edma@3ab00000 {
            compatible = "qcom,edma";
            reg = <0x3AB00000 0xABE00>;
            reg-names = "edma-reg-base";
            qcom,txdesc-ring-start = <0x17>;
            qcom,txdesc-rings = <0x1>;
            qcom,txcmpl-ring-start = <0x17>;
            qcom,txcmpl-rings = <0x1>;
            qcom,rxfill-ring-start = <0x7>;
            qcom,rxfill-rings = <0x1>;
            qcom,rxdesc-ring-start = <0xF>;
            qcom,rxdesc-rings = <0x1>;
            interrupts = <0x0 0x17A 0x4 0x0 0x162 0x4 0x0 0x15A 0x4 0x0 0x17B 0x4>;
            resets = <0x3 0x6D>;
            reset-names = "edma_rst";
        };
        nss-common {
            compatible = "qcom,nss-common";
            reg = <0x1868010 0x1000 0x40000000 0x1000>;
            reg-names = "nss-misc-reset", "nss-misc-reset-flag";
        };
        nss@40000000 {
            compatible = "qcom,nss";
            interrupts = <0x0 0x192 0x1 0x0 0x191 0x1 0x0 0x190 0x1 0x0 0x18F 0x1 0x0 0x18E 0x1 0x0 0x18D 0x1 0x0 0x18C 0x1 0x0 0x18B 0x1 0x0 0x18A 0x1 0x0 0x189 0x1>;
            reg = <0x39000000 0x1000 0xB111000 0x1000>;
            reg-names = "nphys", "qgic-phys";
            clocks = <0x3 0x64 0x3 0x72 0x3 0x61 0x3 0x5F 0x3 0x78 0x3 0xAE 0x3 0x79 0x3 0xF4 0x3 0x5E 0x3 0x5D 0x3 0x74 0x3 0x73 0x3 0x7A 0x3 0x82 0x3 0x80 0x3 0x81 0x3 0xAF 0x3 0xF0 0x3 0xF2>;
            clock-names = "nss-noc-clk", "nss-ptp-ref-clk", "nss-csr-clk", "nss-cfg-clk", "nss-nssnoc-qosgen-ref-clk", "nss-nssnoc-snoc-clk", "nss-nssnoc-timeout-ref-clk", "nss-mem-noc-ubi32-clk", "nss-ce-axi-clk", "nss-ce-apb-clk", "nss-nssnoc-ce-axi-clk", "nss-nssnoc-ce-apb-clk", "nss-nssnoc-ahb-clk", "nss-core-clk", "nss-ahb-clk", "nss-axi-clk", "nss-nc-axi-clk", "nss-utcm-clk", "nss-snoc-nssnoc-clk";
            qcom,id = <0x0>;
            qcom,num-queue = <0x4>;
            qcom,num-irq = <0xA>;
            qcom,num-pri = <0x4>;
            qcom,load-addr = <0x40000000>;
            qcom,low-frequency = "(r";
            qcom,mid-frequency = <0x2CA1C800>;
            qcom,max-frequency = <0x59439000>;
            qcom,bridge-enabled;
            qcom,ipv4-enabled;
            qcom,ipv4-reasm-enabled;
            qcom,ipv6-enabled;
            qcom,ipv6-reasm-enabled;
            qcom,wlanredirect-enabled;
            qcom,tun6rd-enabled;
            qcom,l2tpv2-enabled;
            qcom,gre-enabled;
            qcom,gre-redir-enabled;
            qcom,gre-redir-mark-enabled;
            qcom,map-t-enabled;
            qcom,portid-enabled;
            qcom,ppe-enabled;
            qcom,pppoe-enabled;
            qcom,pptp-enabled;
            qcom,tunipip6-enabled;
            qcom,shaping-enabled;
            qcom,wlan-dataplane-offload-enabled;
            qcom,vlan-enabled;
            qcom,capwap-enabled;
            qcom,dtls-enabled;
            qcom,tls-enabled;
            qcom,crypto-enabled;
            qcom,ipsec-enabled;
            qcom,qvpn-enabled;
            qcom,pvxlan-enabled;
            qcom,clmap-enabled;
            qcom,vxlan-enabled;
            qcom,match-enabled;
            qcom,mirror-enabled;
        };
        qcom,nss_crypto {
            compatible = "qcom,nss-crypto";
            #address-cells = <0x1>;
            #size-cells = <0x1>;
            qcom,max-contexts = <0x40>;
            qcom,max-context-size = <0x20>;
            ranges;
            status = "ok";
            eip197_node {
                compatible = "qcom,eip197";
                reg-names = "crypto_pbase";
                reg = <0x39800000 0x7FFFF>;
                clocks = <0x3 0x60 0x3 0x75 0x3 0x5C>;
                clock-names = "crypto_clk", "crypto_nocclk", "crypto_ppeclk";
                clock-frequency = <0x0 0x11E1A300 0x0 0x11E1A300 0x0 0x11E1A300>;
                qcom,dma-mask = <0xFF>;
                qcom,transform-enabled;
                qcom,aes128-cbc;
                qcom,aes192-cbc;
                qcom,aes256-cbc;
                qcom,aes128-ctr;
                qcom,aes192-ctr;
                qcom,aes256-ctr;
                qcom,aes128-ecb;
                qcom,aes192-ecb;
                qcom,aes256-ecb;
                qcom,3des-cbc;
                qcom,md5-hash;
                qcom,sha160-hash;
                qcom,sha224-hash;
                qcom,sha256-hash;
                qcom,sha384-hash;
                qcom,sha512-hash;
                qcom,md5-hmac;
                qcom,sha160-hmac;
                qcom,sha224-hmac;
                qcom,sha256-hmac;
                qcom,sha384-hmac;
                qcom,sha512-hmac;
                qcom,aes128-gcm-gmac;
                qcom,aes192-gcm-gmac;
                qcom,aes256-gcm-gmac;
                qcom,aes128-cbc-md5-hmac;
                qcom,aes128-cbc-sha160-hmac;
                qcom,aes192-cbc-md5-hmac;
                qcom,aes192-cbc-sha160-hmac;
                qcom,aes256-cbc-md5-hmac;
                qcom,aes256-cbc-sha160-hmac;
                qcom,aes128-ctr-sha160-hmac;
                qcom,aes192-ctr-sha160-hmac;
                qcom,aes256-ctr-sha160-hmac;
                qcom,aes128-ctr-md5-hmac;
                qcom,aes192-ctr-md5-hmac;
                qcom,aes256-ctr-md5-hmac;
                qcom,3des-cbc-md5-hmac;
                qcom,3des-cbc-sha160-hmac;
                qcom,aes128-cbc-sha256-hmac;
                qcom,aes192-cbc-sha256-hmac;
                qcom,aes256-cbc-sha256-hmac;
                qcom,aes128-ctr-sha256-hmac;
                qcom,aes192-ctr-sha256-hmac;
                qcom,aes256-ctr-sha256-hmac;
                qcom,3des-cbc-sha256-hmac;
                qcom,aes128-cbc-sha384-hmac;
                qcom,aes192-cbc-sha384-hmac;
                qcom,aes256-cbc-sha384-hmac;
                qcom,aes128-ctr-sha384-hmac;
                qcom,aes192-ctr-sha384-hmac;
                qcom,aes256-ctr-sha384-hmac;
                qcom,aes128-cbc-sha512-hmac;
                qcom,aes192-cbc-sha512-hmac;
                qcom,aes256-cbc-sha512-hmac;
                qcom,aes128-ctr-sha512-hmac;
                qcom,aes192-ctr-sha512-hmac;
                qcom,aes256-ctr-sha512-hmac;
                engine0 {
                    reg_offset = <0x80000>;
                    qcom,ifpp-enabled;
                    qcom,ipue-enabled;
                    qcom,ofpp-enabled;
                    qcom,opue-enabled;
                };
            };
        };
        clock-controller@b188000 {
            compatible = "qcom,arm-cortex-acc";
            reg = <0xB188000 0x1000>;
            linux,phandle = <0x4D>;
            phandle = <0x4D>;
        };
        clock-controller@b198000 {
            compatible = "qcom,arm-cortex-acc";
            reg = <0xB198000 0x1000>;
            linux,phandle = <0x50>;
            phandle = <0x50>;
        };
        clock-controller@b1a8000 {
            compatible = "qcom,arm-cortex-acc";
            reg = <0xB1A8000 0x1000>;
            linux,phandle = <0x51>;
            phandle = <0x51>;
        };
        clock-controller@b1b8000 {
            compatible = "qcom,arm-cortex-acc";
            reg = <0xB1B8000 0x1000>;
            linux,phandle = <0x52>;
            phandle = <0x52>;
        };
        pinctrl@1000000 {
            compatible = "qcom,ipq6018-pinctrl";
            reg = <0x1000000 0x300000>;
            interrupts = <0x0 0xD0 0x0>;
            gpio-controller;
            #gpio-cells = <0x2>;
            interrupt-controller;
            #interrupt-cells = <0x2>;
            linux,phandle = <0xC>;
            phandle = <0xC>;
            uart_pins {
                linux,phandle = <0x4>;
                phandle = <0x4>;
                mux {
                    pins = "gpio44", "gpio45";
                    function = "blsp2_uart";
                    drive-strength = <0x8>;
                    bias-pull-down;
                };
            };
            spi_0_pins {
                linux,phandle = <0xE>;
                phandle = <0xE>;
                mux {
                    pins = "gpio38", "gpio39", "gpio40", "gpio41";
                    function = "blsp0_spi";
                    drive-strength = <0x8>;
                    bias-pull-down;
                };
            };
            qpic_pins {
                linux,phandle = <0x1E>;
                phandle = <0x1E>;
                data_0 {
                    pins = "gpio15";
                    function = "qpic_pad0";
                    drive-strength = <0x8>;
                    bias-pull-down;
                };
                data_1 {
                    pins = "gpio12";
                    function = "qpic_pad1";
                    drive-strength = <0x8>;
                    bias-pull-down;
                };
                data_2 {
                    pins = "gpio13";
                    function = "qpic_pad2";
                    drive-strength = <0x8>;
                    bias-pull-down;
                };
                data_3 {
                    pins = "gpio14";
                    function = "qpic_pad3";
                    drive-strength = <0x8>;
                    bias-pull-down;
                };
                data_4 {
                    pins = "gpio5";
                    function = "qpic_pad4";
                    drive-strength = <0x8>;
                    bias-pull-down;
                };
                data_5 {
                    pins = "gpio6";
                    function = "qpic_pad5";
                    drive-strength = <0x8>;
                    bias-pull-down;
                };
                data_6 {
                    pins = "gpio7";
                    function = "qpic_pad6";
                    drive-strength = <0x8>;
                    bias-pull-down;
                };
                data_7 {
                    pins = "gpio8";
                    function = "qpic_pad7";
                    drive-strength = <0x8>;
                    bias-pull-down;
                };
                qpic_pad {
                    pins = "gpio1", "gpio3", "gpio4", "gpio10", "gpio11", "gpio17";
                    function = "qpic_pad";
                    drive-strength = <0x8>;
                    bias-pull-down;
                };
            };
            mdio_pinmux {
                linux,phandle = <0x21>;
                phandle = <0x21>;
                mux_0 {
                    pins = "gpio64";
                    function = "mdc";
                    drive-strength = <0x8>;
                    bias-pull-up;
                };
                mux_1 {
                    pins = "gpio65";
                    function = "mdio";
                    drive-strength = <0x8>;
                    bias-pull-up;
                };
                mux_2 {
                    pins = "gpio75";
                    function = "gpio";
                    bias-pull-up;
                };
            };
            leds_pins {
                linux,phandle = <0x4C>;
                phandle = <0x4C>;
                led_mesh_green {
                    pins = "gpio31";
                    function = "gpio";
                    drive-strength = <0x8>;
                    bias-pull-down;
                };
                led_mesh_red {
                    pins = "gpio32";
                    function = "gpio";
                    drive-strength = <0x8>;
                    bias-pull-down;
                };
                led_lan_green {
                    pins = "gpio33";
                    function = "gpio";
                    drive-strength = <0x8>;
                    bias-pull-down;
                };
                led_wan_blue {
                    pins = "gpio34";
                    function = "gpio";
                    drive-strength = <0x8>;
                    bias-pull-down;
                };
                led_wan_green {
                    pins = "gpio37";
                    function = "gpio";
                    drive-strength = <0x8>;
                    bias-pull-down;
                };
                led_wifi {
                    pins = "gpio35";
                    function = "gpio";
                    drive-strength = <0x8>;
                    bias-pull-down;
                };
            };
        };
        watchdog@b017000 {
            compatible = "qcom,kpss-wdt-ipq6018";
            reg = <0xB017000 0x1000>;
            reg-names = "kpss_wdt";
            interrupt-names = "bark_irq";
            interrupts = <0x0 0x3 0x0>;
            clocks = <0x20>;
            timeout-sec = <0x1E>;
            wdt-max-timeout = <0x20>;
        };
        mdio@90000 {
            #address-cells = <0x1>;
            #size-cells = <0x1>;
            compatible = "qcom,qca-mdio", "qcom,ipq40xx-mdio";
            reg = <0x90000 0x64>;
            status = "ok";
            pinctrl-0 = <0x21>;
            pinctrl-names = "default";
            phy-reset-gpio = <0xC 0x4B 0x0>;
            ethernet-phy@0 {
                reg = <0x0>;
            };
            ethernet-phy@1 {
                reg = <0x1>;
            };
            ethernet-phy@2 {
                reg = <0x2>;
            };
            ethernet-phy@3 {
                reg = <0x3>;
            };
            ethernet-phy@4 {
                reg = <0x4>;
            };
        };
        qcom_q6v5_wcss@CD00000 {
            compatible = "qcom,ipq60xx-wcss-pil";
            firmware = "IPQ6018/q6_fw.mdt";
            m3_firmware = "IPQ6018/m3_fw.mdt";
            reg = <0xCD00000 0x4040 0x4AB000 0x20>;
            reg-names = "qdsp6", "rmb";
            qca,auto-restart;
            qca,extended-intc;
            qcom,wcss-aon-reset-quirk;
            interrupts-extended = <0x1 0x0 0x145 0x1 0x15 0x0 0x0 0x15 0x1 0x0 0x15 0x2 0x0 0x15 0x3 0x0>;
            interrupt-names = "wdog", "fatal", "ready", "handover", "stop-ack";
            resets = <0x3 0x7F 0x3 0x16 0x3 0x17>;
            reset-names = "wcss_aon_reset", "wcss_reset", "wcss_q6_reset";
            qcom,halt-regs = <0x22 0xA000 0xD000 0x0>;
            qcom,smem-states = <0x16 0x0 0x16 0x1>;
            qcom,smem-state-names = "shutdown", "stop";
            memory-region = <0x17 0x18>;
            linux,phandle = <0x25>;
            phandle = <0x25>;
            glink-edge {
                interrupts = <0x0 0x141 0x1>;
                qcom,remote-pid = <0x1>;
                mboxes = <0x23 0x8>;
                global_timer = <0x4A5000>;
                rpm_requests {
                    qcom,glink-channels = "IPCRTR";
                };
            };
        };
        qcom_q6v6_adsp@AB00000 {
            status = "disabled";
            compatible = "qcom,ipq6018-adsp-pil";
            interrupts-extended = <0x1 0x0 0x1E 0x1 0x1B 0x0 0x0 0x1B 0x1 0x0 0x1B 0x2 0x0 0x1B 0x3 0x0>;
            interrupt-names = "wdog", "fatal", "ready", "handover", "stop-ack";
            qcom,smem-states = <0x1C 0x0 0x1C 0x1>;
            qcom,smem-state-names = "shutdown", "stop";
            glink-edge {
                interrupts = <0x0 0x18 0x1>;
                qcom,remote-pid = <0x2>;
                mboxes = <0x24 0x8>;
                rpm_requests {
                    qcom,glink-channels = "IPCRTR";
                };
                qcom,msm_fastrpc_rpmsg {
                    compatible = "qcom,msm-fastrpc-rpmsg";
                    qcom,glink-channels = "fastrpcglink-apps-dsp";
                    qcom,intents = <0x64 0x40>;
                };
            };
        };
        ess-switch@3a000000 {
            compatible = "qcom,ess-switch-ipq60xx";
            reg = <0x3A000000 0x1000000>;
            switch_access_mode = "local bus";
            clocks = <0x3 0xB7 0x3 0xB8 0x3 0x8D 0x3 0x98 0x3 0x99 0x3 0x9C 0x3 0x7B 0x3 0x7C 0x3 0x7D 0x3 0x7E 0x3 0x7F 0x3 0x70 0x3 0x6F 0x3 0x77 0x3 0x76 0x3 0x63 0x3 0x62 0x3 0x71 0x3 0x5B 0x3 0x64 0x3 0xAE 0x3 0x60 0x3 0x72 0x3 0x65 0x3 0x66 0x3 0x67 0x3 0x68 0x3 0x69 0x3 0x6A 0x3 0x6B 0x3 0x6C 0x3 0x6D 0x3 0x6E 0x3 0x8E 0x3 0x8F 0x3 0x90 0x3 0x91 0x3 0x92 0x3 0x93 0x3 0x94 0x3 0x95 0x3 0x96 0x3 0x97 0x3 0x9A 0x3 0x9B 0x3 0xC 0x3 0xD 0x3 0xF2>;
            clock-names = "cmn_ahb_clk", "cmn_sys_clk", "uniphy0_ahb_clk", "uniphy0_sys_clk", "uniphy1_ahb_clk", "uniphy1_sys_clk", "port1_mac_clk", "port2_mac_clk", "port3_mac_clk", "port4_mac_clk", "port5_mac_clk", "nss_ppe_clk", "nss_ppe_cfg_clk", "nssnoc_ppe_clk", "nssnoc_ppe_cfg_clk", "nss_edma_clk", "nss_edma_cfg_clk", "nss_ppe_ipe_clk", "gcc_mdio_ahb_clk", "gcc_nss_noc_clk", "gcc_nssnoc_snoc_clk", "gcc_nss_crypto_clk", "gcc_nss_ptp_ref_clk", "nss_port1_rx_clk", "nss_port1_tx_clk", "nss_port2_rx_clk", "nss_port2_tx_clk", "nss_port3_rx_clk", "nss_port3_tx_clk", "nss_port4_rx_clk", "nss_port4_tx_clk", "nss_port5_rx_clk", "nss_port5_tx_clk", "uniphy0_port1_rx_clk", "uniphy0_port1_tx_clk", "uniphy0_port2_rx_clk", "uniphy0_port2_tx_clk", "uniphy0_port3_rx_clk", "uniphy0_port3_tx_clk", "uniphy0_port4_rx_clk", "uniphy0_port4_tx_clk", "uniphy0_port5_rx_clk", "uniphy0_port5_tx_clk", "uniphy1_port5_rx_clk", "uniphy1_port5_tx_clk", "nss_port5_rx_clk_src", "nss_port5_tx_clk_src", "gcc_snoc_nssnoc_clk";
            resets = <0x3 0x68 0x3 0x69 0x3 0x6A 0x3 0x6B 0x3 0x6C 0x3 0x70 0x3 0x71 0x3 0x72 0x3 0x73 0x3 0x74 0x3 0x75 0x3 0x76 0x3 0x77 0x3 0x78 0x3 0x79 0x3 0x7A 0x3 0x7B>;
            reset-names = "ppe_rst", "uniphy0_soft_rst", "uniphy0_xpcs_rst", "uniphy1_soft_rst", "uniphy1_xpcs_rst", "nss_port1_rst", "nss_port2_rst", "nss_port3_rst", "nss_port4_rst", "nss_port5_rst", "uniphy0_port1_dis", "uniphy0_port2_dis", "uniphy0_port3_dis", "uniphy0_port4_dis", "uniphy0_port5_dis", "uniphy0_port_4_5_rst", "uniphy0_port_4_rst";
            switch_cpu_bmp = <0x1>;
            switch_lan_bmp = <0x3E>;
            switch_wan_bmp = <0x40>;
            switch_inner_bmp = <0x80>;
            switch_mac_mode = <0x0>;
            switch_mac_mode1 = <0xFF>;
            switch_mac_mode2 = <0xFF>;
            bm_tick_mode = <0x0>;
            tm_tick_mode = <0x0>;
            port_scheduler_resource {
                port@0 {
                    port_id = <0x0>;
                    ucast_queue = <0x0 0x8F>;
                    mcast_queue = <0x100 0x10F>;
                    l0sp = <0x0 0x23>;
                    l0cdrr = <0x0 0x2F>;
                    l0edrr = <0x0 0x2F>;
                    l1cdrr = <0x0 0x7>;
                    l1edrr = <0x0 0x7>;
                };
                port@1 {
                    port_id = <0x1>;
                    ucast_queue = <0x90 0x9F>;
                    mcast_queue = <0x110 0x113>;
                    l0sp = <0x24 0x27>;
                    l0cdrr = <0x30 0x3F>;
                    l0edrr = <0x30 0x3F>;
                    l1cdrr = <0x8 0xB>;
                    l1edrr = <0x8 0xB>;
                };
                port@2 {
                    port_id = <0x2>;
                    ucast_queue = <0xA0 0xAF>;
                    mcast_queue = <0x114 0x117>;
                    l0sp = <0x28 0x2B>;
                    l0cdrr = <0x40 0x4F>;
                    l0edrr = <0x40 0x4F>;
                    l1cdrr = <0xC 0xF>;
                    l1edrr = <0xC 0xF>;
                };
                port@3 {
                    port_id = <0x3>;
                    ucast_queue = <0xB0 0xBF>;
                    mcast_queue = <0x118 0x11B>;
                    l0sp = <0x2C 0x2F>;
                    l0cdrr = <0x50 0x5F>;
                    l0edrr = <0x50 0x5F>;
                    l1cdrr = <0x10 0x13>;
                    l1edrr = <0x10 0x13>;
                };
                port@4 {
                    port_id = <0x4>;
                    ucast_queue = <0xC0 0xCF>;
                    mcast_queue = <0x11C 0x11F>;
                    l0sp = <0x30 0x33>;
                    l0cdrr = <0x60 0x6F>;
                    l0edrr = <0x60 0x6F>;
                    l1cdrr = <0x14 0x17>;
                    l1edrr = <0x14 0x17>;
                };
                port@5 {
                    port_id = <0x5>;
                    ucast_queue = <0xD0 0xDF>;
                    mcast_queue = <0x120 0x123>;
                    l0sp = <0x34 0x37>;
                    l0cdrr = <0x70 0x7F>;
                    l0edrr = <0x70 0x7F>;
                    l1cdrr = <0x18 0x1B>;
                    l1edrr = <0x18 0x1B>;
                };
                port@6 {
                    port_id = <0x6>;
                    ucast_queue = <0xE0 0xEF>;
                    mcast_queue = <0x124 0x127>;
                    l0sp = <0x38 0x3B>;
                    l0cdrr = <0x80 0x8F>;
                    l0edrr = <0x80 0x8F>;
                    l1cdrr = <0x1C 0x1F>;
                    l1edrr = <0x1C 0x1F>;
                };
                port@7 {
                    port_id = <0x7>;
                    ucast_queue = <0xF0 0xFF>;
                    mcast_queue = <0x128 0x12B>;
                    l0sp = <0x3C 0x3F>;
                    l0cdrr = <0x90 0x9F>;
                    l0edrr = <0x90 0x9F>;
                    l1cdrr = <0x20 0x23>;
                    l1edrr = <0x20 0x23>;
                };
            };
            port_scheduler_config {
                port@0 {
                    port_id = <0x0>;
                    l1scheduler {
                        group@0 {
                            sp = <0x0 0x1>;
                            cfg = <0x0 0x0 0x0 0x0>;
                        };
                    };
                    l0scheduler {
                        group@0 {
                            ucast_queue = <0x0 0x4 0x8>;
                            mcast_queue = <0x100 0x104>;
                            cfg = <0x0 0x0 0x0 0x0 0x0>;
                        };
                        group@1 {
                            ucast_queue = <0x1 0x5 0x9>;
                            mcast_queue = <0x101 0x105>;
                            cfg = <0x0 0x1 0x1 0x1 0x1>;
                        };
                        group@2 {
                            ucast_queue = <0x2 0x6 0xA>;
                            mcast_queue = <0x102 0x106>;
                            cfg = <0x0 0x2 0x2 0x2 0x2>;
                        };
                        group@3 {
                            ucast_queue = <0x3 0x7 0xB>;
                            mcast_queue = <0x103 0x107>;
                            cfg = <0x0 0x3 0x3 0x3 0x3>;
                        };
                    };
                };
                port@1 {
                    port_id = <0x1>;
                    l1scheduler {
                        group@0 {
                            sp = <0x24>;
                            cfg = <0x0 0x8 0x0 0x8>;
                        };
                        group@1 {
                            sp = <0x25>;
                            cfg = <0x1 0x9 0x1 0x9>;
                        };
                    };
                    l0scheduler {
                        group@0 {
                            ucast_queue = <0x90>;
                            ucast_loop_pri = <0x10>;
                            mcast_queue = <0x110>;
                            mcast_loop_pri = <0x4>;
                            cfg = <0x24 0x0 0x30 0x0 0x30>;
                        };
                    };
                };
                port@2 {
                    port_id = <0x2>;
                    l1scheduler {
                        group@0 {
                            sp = <0x28>;
                            cfg = <0x0 0xC 0x0 0xC>;
                        };
                        group@1 {
                            sp = <0x29>;
                            cfg = <0x1 0xD 0x1 0xD>;
                        };
                    };
                    l0scheduler {
                        group@0 {
                            ucast_queue = <0xA0>;
                            ucast_loop_pri = <0x10>;
                            mcast_queue = <0x114>;
                            mcast_loop_pri = <0x4>;
                            cfg = <0x28 0x0 0x40 0x0 0x40>;
                        };
                    };
                };
                port@3 {
                    port_id = <0x3>;
                    l1scheduler {
                        group@0 {
                            sp = <0x2C>;
                            cfg = <0x0 0x10 0x0 0x10>;
                        };
                        group@1 {
                            sp = <0x2D>;
                            cfg = <0x1 0x11 0x1 0x11>;
                        };
                    };
                    l0scheduler {
                        group@0 {
                            ucast_queue = <0xB0>;
                            ucast_loop_pri = <0x10>;
                            mcast_queue = <0x118>;
                            mcast_loop_pri = <0x4>;
                            cfg = <0x2C 0x0 0x50 0x0 0x50>;
                        };
                    };
                };
                port@4 {
                    port_id = <0x4>;
                    l1scheduler {
                        group@0 {
                            sp = <0x30>;
                            cfg = <0x0 0x14 0x0 0x14>;
                        };
                        group@1 {
                            sp = <0x31>;
                            cfg = <0x1 0x15 0x1 0x15>;
                        };
                    };
                    l0scheduler {
                        group@0 {
                            ucast_queue = <0xC0>;
                            ucast_loop_pri = <0x10>;
                            mcast_queue = <0x11C>;
                            mcast_loop_pri = <0x4>;
                            cfg = <0x30 0x0 0x60 0x0 0x60>;
                        };
                    };
                };
                port@5 {
                    port_id = <0x5>;
                    l1scheduler {
                        group@0 {
                            sp = <0x34>;
                            cfg = <0x0 0x18 0x0 0x18>;
                        };
                        group@1 {
                            sp = <0x35>;
                            cfg = <0x1 0x19 0x1 0x19>;
                        };
                    };
                    l0scheduler {
                        group@0 {
                            ucast_queue = <0xD0>;
                            ucast_loop_pri = <0x10>;
                            mcast_queue = <0x120>;
                            mcast_loop_pri = <0x4>;
                            cfg = <0x34 0x0 0x70 0x0 0x70>;
                        };
                    };
                };
                port@6 {
                    port_id = <0x6>;
                    l1scheduler {
                        group@0 {
                            sp = <0x38>;
                            cfg = <0x0 0x1C 0x0 0x1C>;
                        };
                        group@1 {
                            sp = <0x39>;
                            cfg = <0x1 0x1D 0x1 0x1D>;
                        };
                    };
                    l0scheduler {
                        group@0 {
                            ucast_queue = <0xE0>;
                            ucast_loop_pri = <0x10>;
                            mcast_queue = <0x124>;
                            mcast_loop_pri = <0x4>;
                            cfg = <0x38 0x0 0x80 0x0 0x80>;
                        };
                    };
                };
                port@7 {
                    port_id = <0x7>;
                    l1scheduler {
                        group@0 {
                            sp = <0x3C>;
                            cfg = <0x0 0x20 0x0 0x20>;
                        };
                        group@1 {
                            sp = <0x3D>;
                            cfg = <0x1 0x21 0x1 0x21>;
                        };
                    };
                    l0scheduler {
                        group@0 {
                            ucast_queue = <0xF0>;
                            ucast_loop_pri = <0x10>;
                            mcast_queue = <0x128>;
                            cfg = <0x3C 0x0 0x90 0x0 0x90>;
                        };
                    };
                };
            };
            qcom,port_phyinfo {
                port@0 {
                    port_id = <0x1>;
                    phy_address = <0x0>;
                };
                port@2 {
                    port_id = <0x3>;
                    phy_address = <0x2>;
                };
            };
        };
        ess-uniphy@7a00000 {
            compatible = "qcom,ess-uniphy";
            reg = <0x7A00000 0x30000>;
            uniphy_access_mode = "local bus";
        };
        wifi@c000000 {
            compatible = "qcom,cnss-qca6018", "qcom,ipq6018-wifi";
            reg = <0xC000000 0x1000000>;
            qcom,hw-mode-id = <0x1>;
            qcom,tgt-mem-mode = <0x0>;
            qcom,bdf-addr = <0x4ABC0000 0x4ABC0000 0x4ABC0000>;
            qcom,caldb-addr = <0x4B500000 0x4B500000 0x4B500000>;
            qcom,rproc = <0x25>;
            interrupts = <0x0 0x140 0x1 0x0 0x13F 0x1 0x0 0x13E 0x1 0x0 0x13D 0x1 0x0 0x13C 0x1 0x0 0x13B 0x1 0x0 0x13A 0x1 0x0 0x137 0x1 0x0 0x136 0x1 0x0 0x19B 0x1 0x0 0x19A 0x1 0x0 0x28 0x1 0x0 0x27 0x1 0x0 0x12E 0x1 0x0 0x12D 0x1 0x0 0x25 0x1 0x0 0x24 0x1 0x0 0x128 0x1 0x0 0x127 0x1 0x0 0x126 0x1 0x0 0x125 0x1 0x0 0x124 0x1 0x0 0x123 0x1 0x0 0x122 0x1 0x0 0x121 0x1 0x0 0x120 0x1 0x0 0xEF 0x1 0x0 0xEC 0x1 0x0 0xEB 0x1 0x0 0xEA 0x1 0x0 0xE9 0x1 0x0 0xE8 0x1 0x0 0xE7 0x1 0x0 0xE6 0x1 0x0 0xE5 0x1 0x0 0xE4 0x1 0x0 0xE0 0x1 0x0 0xDF 0x1 0x0 0xCB 0x1 0x0 0xB7 0x1 0x0 0xB4 0x1 0x0 0xB3 0x1 0x0 0xB2 0x1 0x0 0xB1 0x1 0x0 0xB0 0x1 0x0 0xA3 0x1 0x0 0xA2 0x1 0x0 0xA0 0x1 0x0 0x9F 0x1 0x0 0x9E 0x1 0x0 0x9D 0x1 0x0 0x9C 0x1>;
            interrupt-names = "misc-pulse1", "misc-latch", "sw-exception", "watchdog", "ce0", "ce1", "ce2", "ce3", "ce4", "ce5", "ce6", "ce7", "ce8", "ce9", "ce10", "ce11", "host2wbm-desc-feed", "host2reo-re-injection", "host2reo-command", "host2rxdma-monitor-ring3", "host2rxdma-monitor-ring2", "host2rxdma-monitor-ring1", "reo2ost-exception", "wbm2host-rx-release", "reo2host-status", "reo2host-destination-ring4", "reo2host-destination-ring3", "reo2host-destination-ring2", "reo2host-destination-ring1", "rxdma2host-monitor-destination-mac3", "rxdma2host-monitor-destination-mac2", "rxdma2host-monitor-destination-mac1", "ppdu-end-interrupts-mac3", "ppdu-end-interrupts-mac2", "ppdu-end-interrupts-mac1", "rxdma2host-monitor-status-ring-mac3", "rxdma2host-monitor-status-ring-mac2", "rxdma2host-monitor-status-ring-mac1", "host2rxdma-host-buf-ring-mac3", "host2rxdma-host-buf-ring-mac2", "host2rxdma-host-buf-ring-mac1", "rxdma2host-destination-ring-mac3", "rxdma2host-destination-ring-mac2", "rxdma2host-destination-ring-mac1", "host2tcl-input-ring4", "host2tcl-input-ring3", "host2tcl-input-ring2", "host2tcl-input-ring1", "wbm2host-tx-completions-ring3", "wbm2host-tx-completions-ring2", "wbm2host-tx-completions-ring1", "tcl2host-status-ring";
            status = "ok";
            qcom,pta-num = <0x0>;
            qcom,coex-mode = <0x2>;
            qcom,bt-active-time = <0x18>;
            qcom,bt-priority-time = <0x12>;
            qcom,coex-algo = <0x2>;
            qcom,pta-priority = <0x80800505>;
        };
        qcom,msm-imem@8600000 {
            compatible = "qcom,msm-imem";
            reg = <0x8600000 0x1000>;
            ranges = <0x0 0x8600000 0x1000>;
            #address-cells = <0x1>;
            #size-cells = <0x1>;
            mem_dump_table@10 {
                compatible = "qcom,msm-imem-mem_dump_table";
                reg = <0x10 0x8>;
            };
        };
        qca,scm_restart_reason {
            compatible = "qca_ipq6018,scm_restart_reason";
            reg = <0x193D000 0x14>;
        };
        slim@a2c0000 {
            cell-index = <0x1>;
            compatible = "qcom,slim-ngd";
            reg = <0xA2C0000 0x2C000 0xA284000 0x2A000>;
            reg-names = "slimbus_physical", "slimbus_bam_physical";
            interrupts = <0x0 0x1F 0x0 0x0 0x20 0x0>;
            interrupt-names = "slimbus_irq", "slimbus_bam_irq";
            qcom,apps-ch-pipes = <0x7C0000>;
            qcom,ea-pc = <0x320>;
            status = "disabled";
        };
        qca,tzlog {
            compatible = "qca,tzlog_ipq6018";
            interrupts = <0x0 0xF4 0x1>;
            qca,tzbsp-diag-buf-size = <0x3000>;
            qca,hyp-enabled;
            hyp-scm-cmd-id = <0xA>;
        };
        qcom,rpm-log@29fc00 {
            compatible = "qcom,rpm-log";
            reg = <0x29FC00 0x4000>;
            qcom,rpm-addr-phys = <0x200000>;
            qcom,offset-version = <0x4>;
            qcom,offset-page-buffer-addr = <0x24>;
            qcom,offset-log-len = <0x28>;
            qcom,offset-log-len-mask = <0x2C>;
            qcom,offset-page-indices = <0x38>;
        };
        qcom,test@0 {
            compatible = "qcom,testmhi";
            status = "disabled";
        };
        tmc@6048000 {
            compatible = "arm,primecell";
            arm,primecell-periphid = <0x3B961>;
            reg = <0x6048000 0x1000 0x6064000 0x15000>;
            reg-names = "tmc-base", "bam-base";
            interrupts = <0x0 0xA6 0x0>;
            interrupt-names = "byte-cntr-irq";
            memory_region = <0x18>;
            arm,buffer-size = <0x100000>;
            arm,sg-enable;
            coresight-ctis = <0x26 0x27>;
            coresight-name = "coresight-tmc-etr";
            clocks = <0x3 0xBF 0x3 0xBE>;
            clock-names = "apb_pclk", "core_a_clk";
            port {
                endpoint {
                    slave-mode;
                    remote-endpoint = <0x28>;
                    linux,phandle = <0x29>;
                    phandle = <0x29>;
                };
            };
        };
        replicator@6046000 {
            compatible = "arm,primecell";
            arm,primecell-periphid = <0x3B909>;
            reg = <0x6046000 0x1000>;
            reg-names = "replicator-base";
            coresight-name = "coresight-replicator";
            clocks = <0x3 0xBF 0x3 0xBE>;
            clock-names = "apb_pclk", "core_a_clk";
            ports {
                #address-cells = <0x1>;
                #size-cells = <0x0>;
                port@0 {
                    reg = <0x0>;
                    endpoint {
                        remote-endpoint = <0x29>;
                        linux,phandle = <0x28>;
                        phandle = <0x28>;
                    };
                };
                port@1 {
                    reg = <0x0>;
                    endpoint {
                        slave-mode;
                        remote-endpoint = <0x2A>;
                        linux,phandle = <0x2B>;
                        phandle = <0x2B>;
                    };
                };
            };
        };
        tmc@6047000 {
            compatible = "arm,primecell";
            arm,primecell-periphid = <0x3B961>;
            reg = <0x6047000 0x1000>;
            reg-names = "tmc-base";
            coresight-ctis = <0x26 0x27>;
            coresight-name = "coresight-tmc-etf";
            arm,default-sink;
            clocks = <0x3 0xBF 0x3 0xBE>;
            clock-names = "apb_pclk", "core_a_clk";
            ports {
                #address-cells = <0x1>;
                #size-cells = <0x0>;
                port@0 {
                    reg = <0x0>;
                    endpoint {
                        remote-endpoint = <0x2B>;
                        linux,phandle = <0x2A>;
                        phandle = <0x2A>;
                    };
                };
                port@1 {
                    reg = <0x0>;
                    endpoint {
                        slave-mode;
                        remote-endpoint = <0x2C>;
                        linux,phandle = <0x2D>;
                        phandle = <0x2D>;
                    };
                };
            };
        };
        funnel@6041000 {
            compatible = "arm,primecell";
            arm,primecell-periphid = <0x3B908>;
            reg = <0x6041000 0x1000>;
            reg-names = "funnel-base";
            coresight-name = "coresight-funnel-in0";
            clocks = <0x3 0xBF 0x3 0xBE>;
            clock-names = "apb_pclk", "core_a_clk";
            ports {
                #address-cells = <0x1>;
                #size-cells = <0x0>;
                port@0 {
                    reg = <0x0>;
                    endpoint {
                        remote-endpoint = <0x2D>;
                        linux,phandle = <0x2C>;
                        phandle = <0x2C>;
                    };
                };
                port@1 {
                    reg = <0x3>;
                    endpoint {
                        slave-mode;
                        remote-endpoint = <0x2E>;
                        linux,phandle = <0x34>;
                        phandle = <0x34>;
                    };
                };
                port@2 {
                    reg = <0x4>;
                    endpoint {
                        slave-mode;
                        remote-endpoint = <0x2F>;
                        linux,phandle = <0x37>;
                        phandle = <0x37>;
                    };
                };
                port@3 {
                    reg = <0x5>;
                    endpoint {
                        slave-mode;
                        remote-endpoint = <0x30>;
                        linux,phandle = <0x36>;
                        phandle = <0x36>;
                    };
                };
                port@4 {
                    reg = <0x6>;
                    endpoint {
                        slave-mode;
                        remote-endpoint = <0x31>;
                        linux,phandle = <0x49>;
                        phandle = <0x49>;
                    };
                };
                port@5 {
                    reg = <0x7>;
                    endpoint {
                        slave-mode;
                        remote-endpoint = <0x32>;
                        linux,phandle = <0x47>;
                        phandle = <0x47>;
                    };
                };
                port@6 {
                    reg = <0x0>;
                    endpoint {
                        slave-mode;
                        remote-endpoint = <0x33>;
                        linux,phandle = <0x46>;
                        phandle = <0x46>;
                    };
                };
            };
        };
        funnel@6100000 {
            compatible = "arm,primecell";
            arm,primecell-periphid = <0x3B908>;
            reg = <0x6100000 0x1000>;
            reg-names = "funnel-base";
            coresight-name = "coresight-funnel-center";
            clocks = <0x3 0xBF 0x3 0xBE>;
            clock-names = "apb_pclk", "core_a_clk";
            ports {
                #address-cells = <0x1>;
                #size-cells = <0x0>;
                port@0 {
                    reg = <0x0>;
                    endpoint {
                        remote-endpoint = <0x34>;
                        linux,phandle = <0x2E>;
                        phandle = <0x2E>;
                    };
                };
                port@1 {
                    reg = <0x2>;
                    endpoint {
                        slave-mode;
                        remote-endpoint = <0x35>;
                        linux,phandle = <0x48>;
                        phandle = <0x48>;
                    };
                };
            };
        };
        funnel@6130000 {
            compatible = "arm,primecell";
            arm,primecell-periphid = <0x3B908>;
            reg = <0x6130000 0x1000>;
            reg-names = "funnel-base";
            coresight-name = "coresight-funnel-mm";
            clocks = <0x3 0xBF 0x3 0xBE>;
            clock-names = "apb_pclk", "core_a_clk";
            ports {
                #address-cells = <0x1>;
                #size-cells = <0x0>;
                port@0 {
                    reg = <0x0>;
                    endpoint {
                        remote-endpoint = <0x36>;
                        linux,phandle = <0x30>;
                        phandle = <0x30>;
                    };
                };
            };
        };
        funnel@6120000 {
            compatible = "arm,primecell";
            arm,primecell-periphid = <0x3B908>;
            reg = <0x6120000 0x1000>;
            reg-names = "funnel-base";
            coresight-name = "coresight-funnel-right";
            clocks = <0x3 0xBF 0x3 0xBE>;
            clock-names = "apb_pclk", "core_a_clk";
            ports {
                #address-cells = <0x1>;
                #size-cells = <0x0>;
                port@0 {
                    reg = <0x0>;
                    endpoint {
                        remote-endpoint = <0x37>;
                        linux,phandle = <0x2F>;
                        phandle = <0x2F>;
                    };
                };
                port@1 {
                    reg = <0x3>;
                    endpoint {
                        slave-mode;
                        remote-endpoint = <0x38>;
                        linux,phandle = <0x39>;
                        phandle = <0x39>;
                    };
                };
            };
        };
        funnel@61a1000 {
            compatible = "arm,primecell";
            arm,primecell-periphid = <0x3B908>;
            reg = <0x61A1000 0x1000>;
            reg-names = "funnel-base";
            coresight-name = "coresight-funnel-apss0";
            clocks = <0x3 0xBF 0x3 0xBE>;
            clock-names = "apb_pclk", "core_a_clk";
            ports {
                #address-cells = <0x1>;
                #size-cells = <0x0>;
                port@0 {
                    reg = <0x0>;
                    endpoint {
                        remote-endpoint = <0x39>;
                        linux,phandle = <0x38>;
                        phandle = <0x38>;
                    };
                };
                port@1 {
                    reg = <0x0>;
                    endpoint {
                        slave-mode;
                        remote-endpoint = <0x3A>;
                        linux,phandle = <0x3F>;
                        phandle = <0x3F>;
                    };
                };
                port@2 {
                    reg = <0x1>;
                    endpoint {
                        slave-mode;
                        remote-endpoint = <0x3B>;
                        linux,phandle = <0x41>;
                        phandle = <0x41>;
                    };
                };
                port@3 {
                    reg = <0x2>;
                    endpoint {
                        slave-mode;
                        remote-endpoint = <0x3C>;
                        linux,phandle = <0x43>;
                        phandle = <0x43>;
                    };
                };
                port@4 {
                    reg = <0x3>;
                    endpoint {
                        slave-mode;
                        remote-endpoint = <0x3D>;
                        linux,phandle = <0x45>;
                        phandle = <0x45>;
                    };
                };
            };
        };
        etm@619c000 {
            compatible = "arm,primecell";
            arm,primecell-periphid = <0x3B95D>;
            reg = <0x619C000 0x1000>;
            coresight-name = "coresight-etm0";
            cpu = <0x3E>;
            clocks = <0x3 0xBF 0x3 0xBE>;
            clock-names = "apb_pclk", "core_a_clk";
            port {
                endpoint {
                    remote-endpoint = <0x3F>;
                    linux,phandle = <0x3A>;
                    phandle = <0x3A>;
                };
            };
        };
        etm@619d000 {
            compatible = "arm,primecell";
            arm,primecell-periphid = <0x3B95D>;
            reg = <0x619D000 0x1000>;
            coresight-name = "coresight-etm1";
            cpu = <0x40>;
            clocks = <0x3 0xBF 0x3 0xBE>;
            clock-names = "apb_pclk", "core_a_clk";
            port {
                endpoint {
                    remote-endpoint = <0x41>;
                    linux,phandle = <0x3B>;
                    phandle = <0x3B>;
                };
            };
        };
        etm@619e000 {
            compatible = "arm,primecell";
            arm,primecell-periphid = <0x3B95D>;
            reg = <0x619E000 0x1000>;
            coresight-name = "coresight-etm2";
            cpu = <0x42>;
            clocks = <0x3 0xBF 0x3 0xBE>;
            clock-names = "apb_pclk", "core_a_clk";
            port {
                endpoint {
                    remote-endpoint = <0x43>;
                    linux,phandle = <0x3C>;
                    phandle = <0x3C>;
                };
            };
        };
        etm@619f000 {
            compatible = "arm,primecell";
            arm,primecell-periphid = <0x3B95D>;
            reg = <0x619F000 0x1000>;
            coresight-name = "coresight-etm3";
            cpu = <0x44>;
            clocks = <0x3 0xBF 0x3 0xBE>;
            clock-names = "apb_pclk", "core_a_clk";
            port {
                endpoint {
                    remote-endpoint = <0x45>;
                    linux,phandle = <0x3D>;
                    phandle = <0x3D>;
                };
            };
        };
        rpm_etm0 {
            compatible = "qcom,coresight-remote-etm";
            coresight-name = "coresight-rpm-etm0";
            qcom,inst-id = <0x4>;
            port {
                endpoint {
                    remote-endpoint = <0x46>;
                    linux,phandle = <0x33>;
                    phandle = <0x33>;
                };
            };
        };
        stm@6002000 {
            compatible = "arm,primecell";
            arm,primecell-periphid = <0x3B962>;
            reg = <0x6002000 0x1000 0x9280000 0x180000>;
            reg-names = "stm-base", "stm-data-base";
            coresight-name = "coresight-stm";
            clocks = <0x3 0xBF 0x3 0xBE>;
            clock-names = "apb_pclk", "core_a_clk";
            port {
                endpoint {
                    remote-endpoint = <0x47>;
                    linux,phandle = <0x32>;
                    phandle = <0x32>;
                };
            };
        };
        cti@6010000 {
            compatible = "arm,coresight-cti";
            reg = <0x6010000 0x1000>;
            reg-names = "cti-base";
            coresight-name = "coresight-cti0";
            clocks = <0x3 0xBF 0x3 0xBE>;
            clock-names = "core_clk", "core_a_clk";
            linux,phandle = <0x26>;
            phandle = <0x26>;
        };
        cti@6011000 {
            compatible = "arm,coresight-cti";
            reg = <0x6011000 0x1000>;
            reg-names = "cti-base";
            coresight-name = "coresight-cti1";
            clocks = <0x3 0xBF 0x3 0xBE>;
            clock-names = "core_clk", "core_a_clk";
        };
        cti@6012000 {
            compatible = "arm,coresight-cti";
            reg = <0x6012000 0x1000>;
            reg-names = "cti-base";
            coresight-name = "coresight-cti2";
            clocks = <0x3 0xBF 0x3 0xBE>;
            clock-names = "core_clk", "core_a_clk";
        };
        cti@6013000 {
            compatible = "arm,coresight-cti";
            reg = <0x6013000 0x1000>;
            reg-names = "cti-base";
            coresight-name = "coresight-cti3";
            clocks = <0x3 0xBF 0x3 0xBE>;
            clock-names = "core_clk", "core_a_clk";
        };
        cti@6014000 {
            compatible = "arm,coresight-cti";
            reg = <0x6014000 0x1000>;
            reg-names = "cti-base";
            coresight-name = "coresight-cti4";
            clocks = <0x3 0xBF 0x3 0xBE>;
            clock-names = "core_clk", "core_a_clk";
        };
        cti@6015000 {
            compatible = "arm,coresight-cti";
            reg = <0x6015000 0x1000>;
            reg-names = "cti-base";
            coresight-name = "coresight-cti5";
            clocks = <0x3 0xBF 0x3 0xBE>;
            clock-names = "core_clk", "core_a_clk";
        };
        cti@6016000 {
            compatible = "arm,coresight-cti";
            reg = <0x6016000 0x1000>;
            reg-names = "cti-base";
            coresight-name = "coresight-cti6";
            clocks = <0x3 0xBF 0x3 0xBE>;
            clock-names = "core_clk", "core_a_clk";
        };
        cti@6017000 {
            compatible = "arm,coresight-cti";
            reg = <0x6017000 0x1000>;
            reg-names = "cti-base";
            coresight-name = "coresight-cti7";
            clocks = <0x3 0xBF 0x3 0xBE>;
            clock-names = "core_clk", "core_a_clk";
        };
        cti@6018000 {
            compatible = "arm,coresight-cti";
            reg = <0x6018000 0x1000>;
            reg-names = "cti-base";
            coresight-name = "coresight-cti8";
            clocks = <0x3 0xBF 0x3 0xBE>;
            clock-names = "core_clk", "core_a_clk";
            linux,phandle = <0x27>;
            phandle = <0x27>;
        };
        cti@6019000 {
            compatible = "arm,coresight-cti";
            reg = <0x6019000 0x1000>;
            reg-names = "cti-base";
            coresight-name = "coresight-cti9";
            clocks = <0x3 0xBF 0x3 0xBE>;
            clock-names = "core_clk", "core_a_clk";
        };
        cti@601a000 {
            compatible = "arm,coresight-cti";
            reg = <0x601A000 0x1000>;
            reg-names = "cti-base";
            coresight-name = "coresight-cti10";
            clocks = <0x3 0xBF 0x3 0xBE>;
            clock-names = "core_clk", "core_a_clk";
        };
        cti@601b000 {
            compatible = "arm,coresight-cti";
            reg = <0x601B000 0x1000>;
            reg-names = "cti-base";
            coresight-name = "coresight-cti11";
            clocks = <0x3 0xBF 0x3 0xBE>;
            clock-names = "core_clk", "core_a_clk";
        };
        cti@601c000 {
            compatible = "arm,coresight-cti";
            reg = <0x601C000 0x1000>;
            reg-names = "cti-base";
            coresight-name = "coresight-cti12";
            clocks = <0x3 0xBF 0x3 0xBE>;
            clock-names = "core_clk", "core_a_clk";
        };
        cti@601d000 {
            compatible = "arm,coresight-cti";
            reg = <0x601D000 0x1000>;
            reg-names = "cti-base";
            coresight-name = "coresight-cti13";
            clocks = <0x3 0xBF 0x3 0xBE>;
            clock-names = "core_clk", "core_a_clk";
        };
        cti@601e000 {
            compatible = "arm,coresight-cti";
            reg = <0x601E000 0x1000>;
            reg-names = "cti-base";
            coresight-name = "coresight-cti14";
            clocks = <0x3 0xBF 0x3 0xBE>;
            clock-names = "core_clk", "core_a_clk";
        };
        cti@601f000 {
            compatible = "arm,coresight-cti";
            reg = <0x601F000 0x1000>;
            reg-names = "cti-base";
            coresight-name = "coresight-cti15";
            clocks = <0x3 0xBF 0x3 0xBE>;
            clock-names = "core_clk", "core_a_clk";
        };
        cti@6198000 {
            compatible = "arm,coresight-cti";
            reg = <0x6198000 0x1000>;
            reg-names = "cti-base";
            coresight-name = "coresight-cti-cpu0";
            cpu = <0x3E>;
            clocks = <0x3 0xBF 0x3 0xBE>;
            clock-names = "core_clk", "core_a_clk";
        };
        cti@6199000 {
            compatible = "arm,coresight-cti";
            reg = <0x6199000 0x1000>;
            reg-names = "cti-base";
            coresight-name = "coresight-cti-cpu1";
            cpu = <0x40>;
            clocks = <0x3 0xBF 0x3 0xBE>;
            clock-names = "core_clk", "core_a_clk";
        };
        cti@619a000 {
            compatible = "arm,coresight-cti";
            reg = <0x619A000 0x1000>;
            reg-names = "cti-base";
            coresight-name = "coresight-cti-cpu2";
            cpu = <0x42>;
            clocks = <0x3 0xBF 0x3 0xBE>;
            clock-names = "core_clk", "core_a_clk";
        };
        cti@619b000 {
            compatible = "arm,coresight-cti";
            reg = <0x619B000 0x1000>;
            reg-names = "cti-base";
            coresight-name = "coresight-cti-cpu3";
            cpu = <0x44>;
            clocks = <0x3 0xBF 0x3 0xBE>;
            clock-names = "core_clk", "core_a_clk";
        };
        cti@610c000 {
            compatible = "arm,coresight-cti";
            reg = <0x610C000 0x1000>;
            reg-names = "cti-base";
            coresight-name = "coresight-cti-rpm-cpu0";
            clocks = <0x3 0xBF 0x3 0xBE>;
            clock-names = "core_clk", "core_a_clk";
        };
        csr@6001000 {
            compatible = "qcom,coresight-csr";
            reg = <0x6001000 0x1000>;
            reg-names = "csr-base";
            coresight-name = "coresight-csr";
            qcom,blk-size = <0x1>;
            clocks = <0x3 0xBF 0x3 0xBE>;
            clock-names = "core_clk", "core_a_clk";
        };
        dbgui@6108000 {
            compatible = "qcom,coresight-dbgui";
            reg = <0x6108000 0x1000>;
            reg-names = "dbgui-base";
            coresight-name = "coresight-dbgui";
            qcom,dbgui-addr-offset = <0x30>;
            qcom,dbgui-data-offset = <0x130>;
            qcom,dbgui-size = <0x40>;
            clocks = <0x3 0xBF 0x3 0xBE>;
            clock-names = "core_clk", "core_a_clk";
            port {
                endpoint {
                    remote-endpoint = <0x48>;
                    linux,phandle = <0x35>;
                    phandle = <0x35>;
                };
            };
        };
        tpda@6004000 {
            compatible = "qcom,coresight-tpda";
            reg = <0x6004000 0x1000>;
            reg-names = "tpda-base";
            coresight-name = "coresight-tpda";
            qcom,tpda-atid = <0x40>;
            qcom,cmb-elem-size = <0x0 0x20>;
            clocks = <0x3 0xBF 0x3 0xBE>;
            clock-names = "core_clk", "core_a_clk";
            ports {
                #address-cells = <0x1>;
                #size-cells = <0x0>;
                port@0 {
                    reg = <0x0>;
                    endpoint {
                        remote-endpoint = <0x49>;
                        linux,phandle = <0x31>;
                        phandle = <0x31>;
                    };
                };
                port@1 {
                    reg = <0x0>;
                    endpoint {
                        slave-mode;
                        remote-endpoint = <0x4A>;
                        linux,phandle = <0x4B>;
                        phandle = <0x4B>;
                    };
                };
            };
        };
        tpdm@6110000 {
            compatible = "qcom,coresight-tpdm";
            reg = <0x6110000 0x1000>;
            reg-names = "tpdm-base";
            coresight-name = "coresight-tpdm-dcc";
            clocks = <0x3 0xBF 0x3 0xBE>;
            clock-names = "core_clk", "core_a_clk";
            port {
                endpoint {
                    remote-endpoint = <0x4B>;
                    linux,phandle = <0x4A>;
                    phandle = <0x4A>;
                };
            };
        };
        hwevent@6101000 {
            compatible = "qcom,coresight-hwevent";
            reg = <0x6101000 0x148 0x6101FB0 0x4 0x6121000 0x148 0x6121FB0 0x4 0x6131000 0x148 0x6131FB0 0x4 0x6130FB0 0x4 0x6130000 0x148 0x6041FB0 0x4 0x6041000 0x148>;
            reg-names = "center-wrapper-mux", "center-wrapper-lockaccess", "right-wrapper-mux", "right-wrapper-lockaccess", "mm-wrapper-mux", "mm-wrapper-lockaccess", "mm-fun-lockaccess", "mm-fun", "in-fun-lockaccess", "in-fun";
            coresight-name = "coresight-hwevent";
            clocks = <0x3 0xBF 0x3 0xBE>;
            clock-names = "core_clk", "core_a_clk";
        };
        thermal-sensor@4a8000 {
            compatible = "qcom,ipq6018-tsens";
            reg = <0x4A8000 0x2000>;
            interrupts = <0x0 0xB8 0x0>;
            #thermal-sensor-cells = <0x1>;
            tsens-up-low-int-clr-deassert-quirk;
            status = "ok";
            linux,phandle = <0x53>;
            phandle = <0x53>;
        };
        dp1 {
            device_type = "network";
            compatible = "qcom,nss-dp";
            qcom,id = <0x1>;
            reg = <0x3A001000 0x200>;
            qcom,mactype = <0x0>;
            local-mac-address = [00 00 00 00 00 00];
            qcom,link-poll = <0x1>;
            qcom,phy-mdio-addr = <0x0>;
            phy-mode = "sgmii";
        };
        dp3 {
            device_type = "network";
            compatible = "qcom,nss-dp";
            qcom,id = <0x3>;
            reg = <0x3A001400 0x200>;
            qcom,mactype = <0x0>;
            local-mac-address = [00 00 00 00 00 00];
            qcom,link-poll = <0x1>;
            qcom,phy-mdio-addr = <0x2>;
            phy-mode = "sgmii";
        };
        leds {
            compatible = "gpio-leds";
            pinctrl-0 = <0x4C>;
            pinctrl-names = "default";
            led@31 {
                label = "mesh-green";
                gpios = <0xC 0x1F 0x0>;
                linux,default-trigger = "led_mesh_green";
                default-state = "off";
            };
            led@32 {
                label = "mesh-red";
                gpios = <0xC 0x20 0x0>;
                linux,default-trigger = "led_mesh_red";
                default-state = "off";
            };
            led@33 {
                label = "lan-green";
                gpios = <0xC 0x21 0x0>;
                linux,default-trigger = "led_lan_green";
                default-state = "off";
            };
            led@34 {
                label = "wan-blue";
                gpios = <0xC 0x22 0x0>;
                linux,default-trigger = "led_wan_blue";
                default-state = "off";
            };
            led@37 {
                label = "wan-green";
                gpios = <0xC 0x25 0x0>;
                linux,default-trigger = "led_wan_green";
                default-state = "off";
            };
            led@35 {
                label = "wifi-green";
                gpios = <0xC 0x23 0x0>;
                linux,default-trigger = "led_wifi";
                default-state = "off";
            };
        };
        pmu {
            compatible = "arm,cortex-a7-pmu";
            interrupts = <0x1 0x7 0xF04>;
        };
    };
    psci {
        compatible = "arm,psci-1.0";
        method = "smc";
        status = "ok";
    };
    cpus {
        #address-cells = <0x1>;
        #size-cells = <0x0>;
        cpu@0 {
            device_type = "cpu";
            compatible = "arm,cortex-a53", "arm,armv8";
            reg = <0x0>;
            enable-method = "psci";
            qcom,acc = <0x4D>;
            next-level-cache = <0x4E>;
            clocks = <0x4F 0x3>;
            clock-names = "cpu";
            operating-points = <0xD2F00 0x10C8E0 0x101D00 0x10C8E0 0x142440 0x10C8E0 0x15F900 0x10C8E0 0x188940 0x10C8E0 0x1B7740 0x10C8E0>;
            clock-latency = <0x30D40>;
            linux,phandle = <0x3E>;
            phandle = <0x3E>;
            l2-cache {
                compatible = "cache";
                cache-level = <0x2>;
                linux,phandle = <0x4E>;
                phandle = <0x4E>;
            };
        };
        cpu@1 {
            device_type = "cpu";
            compatible = "arm,cortex-a53", "arm,armv8";
            enable-method = "psci";
            qcom,acc = <0x50>;
            reg = <0x1>;
            next-level-cache = <0x4E>;
            clocks = <0x4F 0x3>;
            clock-names = "cpu";
            operating-points = <0xD2F00 0x10C8E0 0x101D00 0x10C8E0 0x142440 0x10C8E0 0x15F900 0x10C8E0 0x188940 0x10C8E0 0x1B7740 0x10C8E0>;
            clock-latency = <0x30D40>;
            linux,phandle = <0x40>;
            phandle = <0x40>;
        };
        cpu@2 {
            device_type = "cpu";
            compatible = "arm,cortex-a53", "arm,armv8";
            enable-method = "psci";
            qcom,acc = <0x51>;
            reg = <0x2>;
            next-level-cache = <0x4E>;
            clocks = <0x4F 0x3>;
            clock-names = "cpu";
            operating-points = <0xD2F00 0x10C8E0 0x101D00 0x10C8E0 0x142440 0x10C8E0 0x15F900 0x10C8E0 0x188940 0x10C8E0 0x1B7740 0x10C8E0>;
            clock-latency = <0x30D40>;
            linux,phandle = <0x42>;
            phandle = <0x42>;
        };
        cpu@3 {
            device_type = "cpu";
            compatible = "arm,cortex-a53", "arm,armv8";
            enable-method = "psci";
            qcom,acc = <0x52>;
            reg = <0x3>;
            next-level-cache = <0x4E>;
            clocks = <0x4F 0x3>;
            clock-names = "cpu";
            operating-points = <0xD2F00 0x10C8E0 0x101D00 0x10C8E0 0x142440 0x10C8E0 0x15F900 0x10C8E0 0x188940 0x10C8E0 0x1B7740 0x10C8E0>;
            clock-latency = <0x30D40>;
            linux,phandle = <0x44>;
            phandle = <0x44>;
        };
    };
    qseecom {
        compatible = "ipq6018-qseecom";
        status = "ok";
        mem-start = <0x49B00000>;
        mem-size = <0x600000>;
    };
    firmware {
        scm {
            compatible = "qcom,scm-ipq6018";
            smmu-state-scm-cmd-id = <0x20>;
        };
        qfprom {
            compatible = "qcom,qfprom-sec";
            img-addr = <0x4A100000>;
            img-size = <0x500000>;
            scm-cmd-id = <0x1F>;
        };
    };
    pmu {
        compatible = "arm,cortex-a53-pmu";
        interrupts = <0x1 0x7 0xF04>;
    };
    clocks {
        sleep_clk {
            compatible = "fixed-clock";
            clock-frequency = <0x7D00>;
            #clock-cells = <0x0>;
            linux,phandle = <0x20>;
            phandle = <0x20>;
        };
        xo {
            compatible = "fixed-clock";
            clock-frequency = <0x16E3600>;
            #clock-cells = <0x0>;
        };
        bias_pll_cc_clk {
            compatible = "fixed-clock";
            clock-frequency = <0x11E1A300>;
            #clock-cells = <0x0>;
        };
        bias_pll_nss_noc_clk {
            compatible = "fixed-clock";
            clock-frequency = <0x18D34920>;
            #clock-cells = <0x0>;
        };
        usb3phy_0_cc_pipe_clk {
            compatible = "fixed-clock";
            clock-frequency = <0x7735940>;
            #clock-cells = <0x0>;
        };
    };
    ion_dummy {
        compatible = "ipq60xx-ion-dummy";
        status = "disabled";
    };
    thermal-zones {
        tsens_tz_sensor4 {
            polling-delay-passive = <0x0>;
            polling-delay = <0x0>;
            thermal-sensors = <0x53 0x4>;
            trips {
                cpu-critical-hi {
                    temperature = <0x7D>;
                    hysteresis = <0x2>;
                    type = "critical_high";
                };
                cpu-config-hi {
                    temperature = <0x69>;
                    hysteresis = <0x2>;
                    type = "configurable_hi";
                };
                cpu-config-lo {
                    temperature = <0x5F>;
                    hysteresis = <0x2>;
                    type = "configurable_lo";
                };
                cpu-critical-low {
                    temperature = <0x0>;
                    hysteresis = <0x2>;
                    type = "critical_low";
                };
            };
        };
        tsens_tz_sensor5 {
            polling-delay-passive = <0x0>;
            polling-delay = <0x0>;
            thermal-sensors = <0x53 0x5>;
            trips {
                cpu-critical-hi {
                    temperature = <0x7D>;
                    hysteresis = <0x2>;
                    type = "critical_high";
                };
                cpu-config-hi {
                    temperature = <0x69>;
                    hysteresis = <0x2>;
                    type = "configurable_hi";
                };
                cpu-config-lo {
                    temperature = <0x5F>;
                    hysteresis = <0x2>;
                    type = "configurable_lo";
                };
                cpu-critical-low {
                    temperature = <0x0>;
                    hysteresis = <0x2>;
                    type = "critical_low";
                };
            };
        };
        tsens_tz_sensor7 {
            polling-delay-passive = <0x0>;
            polling-delay = <0x0>;
            thermal-sensors = <0x53 0x7>;
            trips {
                cpu-critical-hi {
                    temperature = <0x7D>;
                    hysteresis = <0x2>;
                    type = "critical_high";
                };
                cpu-config-hi {
                    temperature = <0x69>;
                    hysteresis = <0x2>;
                    type = "configurable_hi";
                };
                cpu-config-lo {
                    temperature = <0x5F>;
                    hysteresis = <0x2>;
                    type = "configurable_lo";
                };
                cpu-critical-low {
                    temperature = <0x0>;
                    hysteresis = <0x2>;
                    type = "critical_low";
                };
            };
        };
        tsens_tz_sensor8 {
            polling-delay-passive = <0x0>;
            polling-delay = <0x0>;
            thermal-sensors = <0x53 0x8>;
            trips {
                cpu-critical-hi {
                    temperature = <0x7D>;
                    hysteresis = <0x2>;
                    type = "critical_high";
                };
                cpu-config-hi {
                    temperature = <0x69>;
                    hysteresis = <0x2>;
                    type = "configurable_hi";
                };
                cpu-config-lo {
                    temperature = <0x5F>;
                    hysteresis = <0x2>;
                    type = "configurable_lo";
                };
                cpu-critical-low {
                    temperature = <0x0>;
                    hysteresis = <0x2>;
                    type = "critical_low";
                };
            };
        };
        tsens_tz_sensor13 {
            polling-delay-passive = <0x0>;
            polling-delay = <0x0>;
            thermal-sensors = <0x53 0xD>;
            trips {
                cpu-critical-hi {
                    temperature = <0x7D>;
                    hysteresis = <0x2>;
                    type = "critical_high";
                };
                cpu-config-hi {
                    temperature = <0x69>;
                    hysteresis = <0x2>;
                    type = "configurable_hi";
                };
                cpu-config-lo {
                    temperature = <0x5F>;
                    hysteresis = <0x2>;
                    type = "configurable_lo";
                };
                cpu-critical-low {
                    temperature = <0x0>;
                    hysteresis = <0x2>;
                    type = "critical_low";
                };
            };
        };
        tsens_tz_sensor14 {
            polling-delay-passive = <0x0>;
            polling-delay = <0x0>;
            thermal-sensors = <0x53 0xE>;
            trips {
                cpu-critical-hi {
                    temperature = <0x7D>;
                    hysteresis = <0x2>;
                    type = "critical_high";
                };
                cpu-config-hi {
                    temperature = <0x69>;
                    hysteresis = <0x2>;
                    type = "configurable_hi";
                };
                cpu-config-lo {
                    temperature = <0x5F>;
                    hysteresis = <0x2>;
                    type = "configurable_lo";
                };
                cpu-critical-low {
                    temperature = <0x0>;
                    hysteresis = <0x2>;
                    type = "critical_low";
                };
            };
        };
        tsens_tz_sensor15 {
            polling-delay-passive = <0x0>;
            polling-delay = <0x0>;
            thermal-sensors = <0x53 0xF>;
            trips {
                cpu-critical-hi {
                    temperature = <0x7D>;
                    hysteresis = <0x2>;
                    type = "critical_high";
                };
                cpu-config-hi {
                    temperature = <0x69>;
                    hysteresis = <0x2>;
                    type = "configurable_hi";
                };
                cpu-config-lo {
                    temperature = <0x5F>;
                    hysteresis = <0x2>;
                    type = "configurable_lo";
                };
                cpu-critical-low {
                    temperature = <0x0>;
                    hysteresis = <0x2>;
                    type = "critical_low";
                };
            };
        };
    };
    aliases {
        ethernet0 = "/soc/dp1";
        ethernet1 = "/soc/dp2";
    };
    chosen {
        bootargs = "console=ttyMSM0,115200,n8 rw init=/init";
        bootargs-append = " swiotlb=1 coherent_pool=2M";
    };
};
